AUTOSAR XML (schema 4-0-3)
package /ComponentTypes
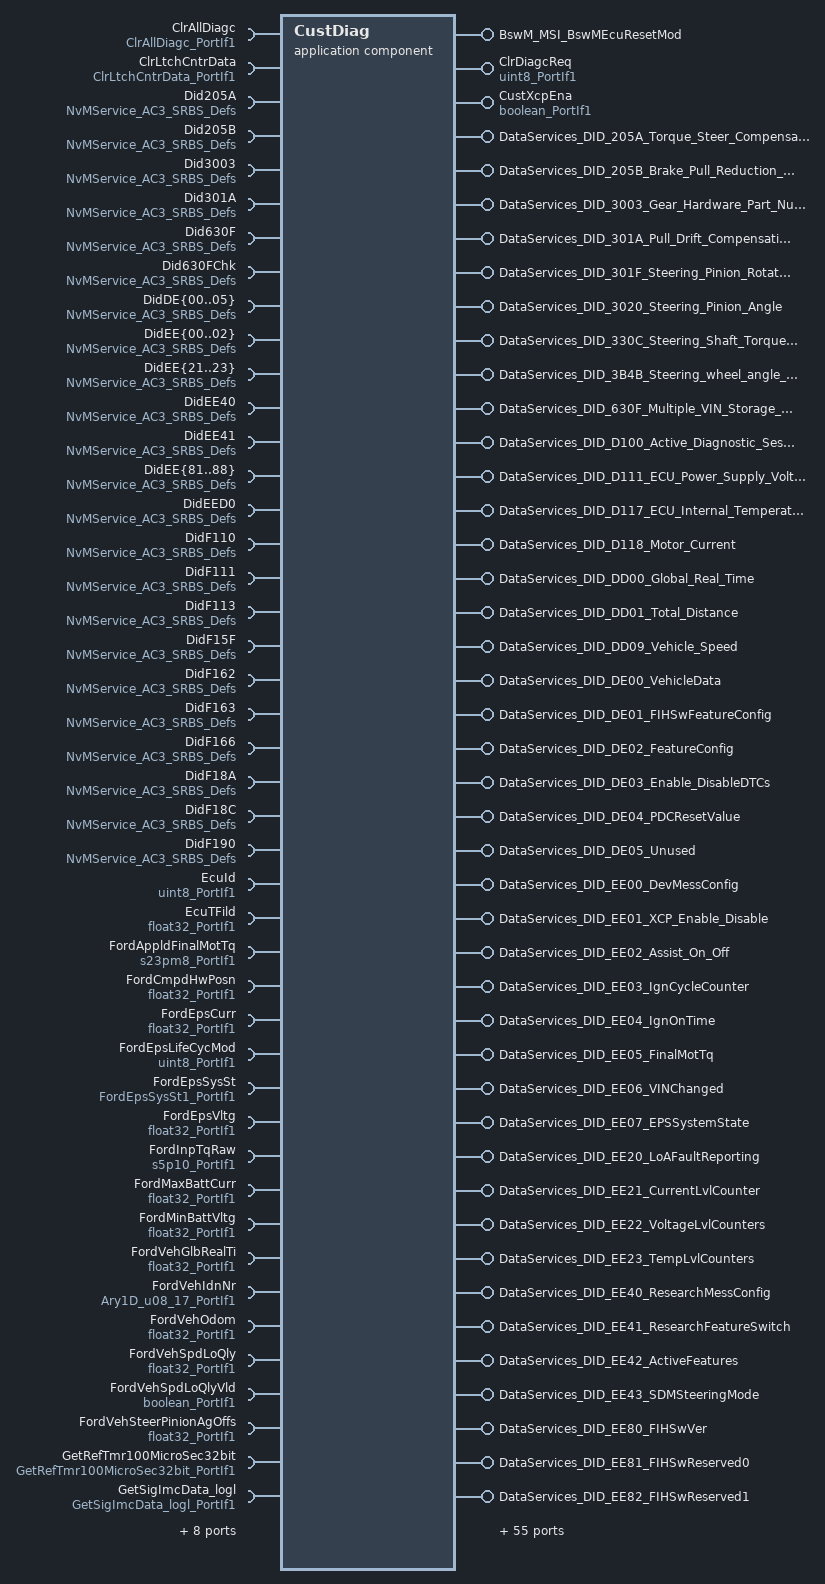
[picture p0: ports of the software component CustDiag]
  application sw component type CustDiag
    99 x provide port:
      BswM_MSI_BswMEcuResetMod: mode-switch-sender-com-spec{enhanced-mode-api=false, mode-group=BswM_MDGP_BswMEcuResetMod, queue-length=1}, provided-interface=BswM_MSI_BswMEcuResetMod
      ClrDiagcReq: nonqueued-sender-com-spec{data-element=Val, init-value=0}, provided-interface=uint8_PortIf1
      CustXcpEna: nonqueued-sender-com-spec{data-element=Logl, init-value=0}, provided-interface=boolean_PortIf1
      DataServices_DID_205A_Torque_Steer_Compensation_Activation_Counter: provided-interface=DataServices_DID_205A_Torque_Steer_Compensation_Activation_Counter
        provided-com-specs:
          operation=ConditionCheckRead, queue-length=1
          operation=ReadData, queue-length=1
          operation=WriteData, queue-length=1
      DataServices_DID_205B_Brake_Pull_Reduction_Activation_Counter: provided-interface=DataServices_DID_205B_Brake_Pull_Reduction_Activation_Counter
        provided-com-specs:
          operation=ConditionCheckRead, queue-length=1
          operation=ReadData, queue-length=1
          operation=WriteData, queue-length=1
      DataServices_DID_3003_Gear_Hardware_Part_Number: provided-interface=DataServices_DID_3003_Gear_Hardware_Part_Number
        provided-com-specs:
          operation=ConditionCheckRead, queue-length=1
          operation=ReadData, queue-length=1
          operation=WriteData, queue-length=1
      DataServices_DID_301A_Pull_Drift_Compensation_Value: provided-interface=DataServices_DID_301A_Pull_Drift_Compensation_Value
        provided-com-specs:
          operation=ConditionCheckRead, queue-length=1
          operation=ReadData, queue-length=1
          operation=WriteData, queue-length=1
      DataServices_DID_301F_Steering_Pinion_Rotation_Speed: provided-com-specs=[{operation=ConditionCheckRead, queue-length=1}, {operation=ReadData, queue-length=1}], provided-interface=DataServices_DID_301F_Steering_Pinion_Rotation_Speed
      DataServices_DID_3020_Steering_Pinion_Angle: provided-com-specs=[{operation=ConditionCheckRead, queue-length=1}, {operation=ReadData, queue-length=1}], provided-interface=DataServices_DID_3020_Steering_Pinion_Angle
      DataServices_DID_330C_Steering_Shaft_Torque_Sensor_2: provided-com-specs=[{operation=ConditionCheckRead, queue-length=1}, {operation=ReadData, queue-length=1}], provided-interface=DataServices_DID_330C_Steering_Shaft_Torque_Sensor_2
      DataServices_DID_3B4B_Steering_wheel_angle_alignment_offset: provided-com-specs=[{operation=ConditionCheckRead, queue-length=1}, {operation=ReadData, queue-length=1}], provided-interface=DataServices_DID_3B4B_Steering_wheel_angle_alignment_offset
      DataServices_DID_630F_Multiple_VIN_Storage_Original_VIN: provided-com-specs=[{operation=ConditionCheckRead, queue-length=1}, {operation=ReadData, queue-length=1}], provided-interface=DataServices_DID_630F_Multiple_VIN_Storage_Original_VIN
      DataServices_DID_D100_Active_Diagnostic_Session: provided-com-specs=[{operation=ConditionCheckRead, queue-length=1}, {operation=ReadData, queue-length=1}], provided-interface=DataServices_DID_D100_Active_Diagnostic_Session
      DataServices_DID_D111_ECU_Power_Supply_Voltage: provided-com-specs=[{operation=ConditionCheckRead, queue-length=1}, {operation=ReadData, queue-length=1}], provided-interface=DataServices_DID_D111_ECU_Power_Supply_Voltage
      DataServices_DID_D117_ECU_Internal_Temperature: provided-com-specs=[{operation=ConditionCheckRead, queue-length=1}, {operation=ReadData, queue-length=1}], provided-interface=DataServices_DID_D117_ECU_Internal_Temperature
      DataServices_DID_D118_Motor_Current: provided-com-specs=[{operation=ConditionCheckRead, queue-length=1}, {operation=ReadData, queue-length=1}], provided-interface=DataServices_DID_D118_Motor_Current
      DataServices_DID_DD00_Global_Real_Time: provided-com-specs=[{operation=ConditionCheckRead, queue-length=1}, {operation=ReadData, queue-length=1}], provided-interface=DataServices_DID_DD00_Global_Real_Time
      DataServices_DID_DD01_Total_Distance: provided-com-specs=[{operation=ConditionCheckRead, queue-length=1}, {operation=ReadData, queue-length=1}], provided-interface=DataServices_DID_DD01_Total_Distance
      DataServices_DID_DD09_Vehicle_Speed: provided-com-specs=[{operation=ConditionCheckRead, queue-length=1}, {operation=ReadData, queue-length=1}], provided-interface=DataServices_DID_DD09_Vehicle_Speed
      DataServices_DID_DE00_VehicleData: provided-interface=DataServices_DID_DE00_VehicleData
        provided-com-specs:
          operation=ConditionCheckRead, queue-length=1
          operation=ReadData, queue-length=1
          operation=WriteData, queue-length=1
      DataServices_DID_DE01_FIHSwFeatureConfig: provided-interface=DataServices_DID_DE01_FIHSwFeatureConfig
        provided-com-specs:
          operation=ConditionCheckRead, queue-length=1
          operation=ReadData, queue-length=1
          operation=WriteData, queue-length=1
      DataServices_DID_DE02_FeatureConfig: provided-interface=DataServices_DID_DE02_FeatureConfig
        provided-com-specs:
          operation=ConditionCheckRead, queue-length=1
          operation=ReadData, queue-length=1
          operation=WriteData, queue-length=1
      DataServices_DID_DE03_Enable_DisableDTCs: provided-interface=DataServices_DID_DE03_Enable_DisableDTCs
        provided-com-specs:
          operation=ConditionCheckRead, queue-length=1
          operation=ReadData, queue-length=1
          operation=WriteData, queue-length=1
      DataServices_DID_DE04_PDCResetValue: provided-interface=DataServices_DID_DE04_PDCResetValue
        provided-com-specs:
          operation=ConditionCheckRead, queue-length=1
          operation=ReadData, queue-length=1
          operation=WriteData, queue-length=1
      DataServices_DID_DE05_Unused: provided-interface=DataServices_DID_DE05_Unused
        provided-com-specs:
          operation=ConditionCheckRead, queue-length=1
          operation=ReadData, queue-length=1
          operation=WriteData, queue-length=1
      DataServices_DID_EE00_DevMessConfig: provided-interface=DataServices_DID_EE00_DevMessConfig
        provided-com-specs:
          operation=ConditionCheckRead, queue-length=1
          operation=ReadData, queue-length=1
          operation=WriteData, queue-length=1
      DataServices_DID_EE01_XCP_Enable_Disable: provided-interface=DataServices_DID_EE01_XCP_Enable_Disable
        provided-com-specs:
          operation=ConditionCheckRead, queue-length=1
          operation=ReadData, queue-length=1
          operation=WriteData, queue-length=1
      DataServices_DID_EE02_Assist_On_Off: provided-interface=DataServices_DID_EE02_Assist_On_Off
        provided-com-specs:
          operation=ConditionCheckRead, queue-length=1
          operation=ReadData, queue-length=1
          operation=WriteData, queue-length=1
      DataServices_DID_EE03_IgnCycleCounter: provided-com-specs=[{operation=ConditionCheckRead, queue-length=1}, {operation=ReadData, queue-length=1}], provided-interface=DataServices_DID_EE03_IgnCycleCounter
      DataServices_DID_EE04_IgnOnTime: provided-com-specs=[{operation=ConditionCheckRead, queue-length=1}, {operation=ReadData, queue-length=1}], provided-interface=DataServices_DID_EE04_IgnOnTime
      DataServices_DID_EE05_FinalMotTq: provided-com-specs=[{operation=ConditionCheckRead, queue-length=1}, {operation=ReadData, queue-length=1}], provided-interface=DataServices_DID_EE05_FinalMotTq
      DataServices_DID_EE06_VINChanged: provided-com-specs=[{operation=ConditionCheckRead, queue-length=1}, {operation=ReadData, queue-length=1}], provided-interface=DataServices_DID_EE06_VINChanged
      DataServices_DID_EE07_EPSSystemState: provided-com-specs=[{operation=ConditionCheckRead, queue-length=1}, {operation=ReadData, queue-length=1}], provided-interface=DataServices_DID_EE07_EPSSystemState
      DataServices_DID_EE20_LoAFaultReporting: provided-com-specs=[{operation=ConditionCheckRead, queue-length=1}, {operation=ReadData, queue-length=1}], provided-interface=DataServices_DID_EE20_LoAFaultReporting
      DataServices_DID_EE21_CurrentLvlCounter: provided-com-specs=[{operation=ConditionCheckRead, queue-length=1}, {operation=ReadData, queue-length=1}], provided-interface=DataServices_DID_EE21_CurrentLvlCounter
      DataServices_DID_EE22_VoltageLvlCounters: provided-com-specs=[{operation=ConditionCheckRead, queue-length=1}, {operation=ReadData, queue-length=1}], provided-interface=DataServices_DID_EE22_VoltageLvlCounters
      DataServices_DID_EE23_TempLvlCounters: provided-com-specs=[{operation=ConditionCheckRead, queue-length=1}, {operation=ReadData, queue-length=1}], provided-interface=DataServices_DID_EE23_TempLvlCounters
      DataServices_DID_EE40_ResearchMessConfig: provided-interface=DataServices_DID_EE40_ResearchMessConfig
        provided-com-specs:
          operation=ConditionCheckRead, queue-length=1
          operation=ReadData, queue-length=1
          operation=WriteData, queue-length=1
      DataServices_DID_EE41_ResearchFeatureSwitch: provided-interface=DataServices_DID_EE41_ResearchFeatureSwitch
        provided-com-specs:
          operation=ConditionCheckRead, queue-length=1
          operation=ReadData, queue-length=1
          operation=WriteData, queue-length=1
      DataServices_DID_EE42_ActiveFeatures: provided-com-specs=[{operation=ConditionCheckRead, queue-length=1}, {operation=ReadData, queue-length=1}], provided-interface=DataServices_DID_EE42_ActiveFeatures
      DataServices_DID_EE43_SDMSteeringMode: provided-com-specs=[{operation=ConditionCheckRead, queue-length=1}, {operation=ReadData, queue-length=1}], provided-interface=DataServices_DID_EE43_SDMSteeringMode
      DataServices_DID_EE80_FIHSwVer: provided-com-specs=[{operation=ConditionCheckRead, queue-length=1}, {operation=ReadData, queue-length=1}], provided-interface=DataServices_DID_EE80_FIHSwVer
      DataServices_DID_EE81_FIHSwReserved0: provided-interface=DataServices_DID_EE81_FIHSwReserved0
        provided-com-specs:
          operation=ConditionCheckRead, queue-length=1
          operation=ReadData, queue-length=1
          operation=WriteData, queue-length=1
      DataServices_DID_EE82_FIHSwReserved1: provided-interface=DataServices_DID_EE82_FIHSwReserved1
        provided-com-specs:
          operation=ConditionCheckRead, queue-length=1
          operation=ReadData, queue-length=1
          operation=WriteData, queue-length=1
      DataServices_DID_EE83_FIHSwReserved2: provided-interface=DataServices_DID_EE83_FIHSwReserved2
        provided-com-specs:
          operation=ConditionCheckRead, queue-length=1
          operation=ReadData, queue-length=1
          operation=WriteData, queue-length=1
      DataServices_DID_EE84_FIHSwReserved3: provided-interface=DataServices_DID_EE84_FIHSwReserved3
        provided-com-specs:
          operation=ConditionCheckRead, queue-length=1
          operation=ReadData, queue-length=1
          operation=WriteData, queue-length=1
      DataServices_DID_EE85_FIHSwReserved4: provided-interface=DataServices_DID_EE85_FIHSwReserved4
        provided-com-specs:
          operation=ConditionCheckRead, queue-length=1
          operation=ReadData, queue-length=1
          operation=WriteData, queue-length=1
      DataServices_DID_EE86_FIHSwReserved5: provided-interface=DataServices_DID_EE86_FIHSwReserved5
        provided-com-specs:
          operation=ConditionCheckRead, queue-length=1
          operation=ReadData, queue-length=1
          operation=WriteData, queue-length=1
      DataServices_DID_EE87_FIHSwReserved6: provided-interface=DataServices_DID_EE87_FIHSwReserved6
        provided-com-specs:
          operation=ConditionCheckRead, queue-length=1
          operation=ReadData, queue-length=1
          operation=WriteData, queue-length=1
      DataServices_DID_EE88_FIHSwReserved7: provided-interface=DataServices_DID_EE88_FIHSwReserved7
        provided-com-specs:
          operation=ConditionCheckRead, queue-length=1
          operation=ReadData, queue-length=1
          operation=WriteData, queue-length=1
      DataServices_DID_EED0_SupplierFactoryMode: provided-interface=DataServices_DID_EED0_SupplierFactoryMode
        provided-com-specs:
          operation=ConditionCheckRead, queue-length=1
          operation=ReadData, queue-length=1
          operation=WriteData, queue-length=1
      DataServices_DID_EED1_SupplierInternalFaultCode: provided-com-specs=[{operation=ConditionCheckRead, queue-length=1}, {operation=ReadData, queue-length=1}], provided-interface=DataServices_DID_EED1_SupplierInternalFaultCode
      DataServices_DID_EED2_SupplierInternalErrorMemory: provided-com-specs=[{operation=ConditionCheckRead, queue-length=1}, {operation=ReadData, queue-length=1}], provided-interface=DataServices_DID_EED2_SupplierInternalErrorMemory
      DataServices_DID_F10A_ECU_Cal_Config_Part_Number: provided-com-specs=[{operation=ConditionCheckRead, queue-length=1}, {operation=ReadData, queue-length=1}], provided-interface=DataServices_DID_F10A_ECU_Cal_Config_Part_Number
      DataServices_DID_F110_Subsystem_Specific_Diagnostic_Specification_Part_Number: provided-interface=DataServices_DID_F110_Subsystem_Specific_Diagnostic_Specification_Part_Number
        provided-com-specs:
          operation=ConditionCheckRead, queue-length=1
          operation=ReadData, queue-length=1
          operation=WriteData, queue-length=1
      DataServices_DID_F111_ECU_Core_Assembly_Number: provided-interface=DataServices_DID_F111_ECU_Core_Assembly_Number
        provided-com-specs:
          operation=ConditionCheckRead, queue-length=1
          operation=ReadData, queue-length=1
          operation=WriteData, queue-length=1
      DataServices_DID_F113_ECU_Delivery_Assembly_Number: provided-interface=DataServices_DID_F113_ECU_Delivery_Assembly_Number
        provided-com-specs:
          operation=ConditionCheckRead, queue-length=1
          operation=ReadData, queue-length=1
          operation=WriteData, queue-length=1
      DataServices_DID_F124_ECU_Calibration_Data_1_Number: provided-com-specs=[{operation=ConditionCheckRead, queue-length=1}, {operation=ReadData, queue-length=1}], provided-interface=DataServices_DID_F124_ECU_Calibration_Data_1_Number
      DataServices_DID_F15F_NOS_Generation_Tool_Version_Number: provided-com-specs=[{operation=ConditionCheckRead, queue-length=1}, {operation=ReadData, queue-length=1}], provided-interface=DataServices_DID_F15F_NOS_Generation_Tool_Version_Number
      DataServices_DID_F162_Software_Download_Specification_Version: provided-interface=DataServices_DID_F162_Software_Download_Specification_Version
        provided-com-specs:
          operation=ConditionCheckRead, queue-length=1
          operation=ReadData, queue-length=1
          operation=WriteData, queue-length=1
      DataServices_DID_F163_Diagnostic_Specification_Version: provided-interface=DataServices_DID_F163_Diagnostic_Specification_Version
        provided-com-specs:
          operation=ConditionCheckRead, queue-length=1
          operation=ReadData, queue-length=1
          operation=WriteData, queue-length=1
      DataServices_DID_F166_NOS_Message_Database_1_Version_Number: provided-interface=DataServices_DID_F166_NOS_Message_Database_1_Version_Number
        provided-com-specs:
          operation=ConditionCheckRead, queue-length=1
          operation=ReadData, queue-length=1
          operation=WriteData, queue-length=1
      DataServices_DID_F17C_NOS_Bootloader_Generation_Tool_Version_Number: provided-com-specs=[{operation=ConditionCheckRead, queue-length=1}, {operation=ReadData, queue-length=1}], provided-interface=DataServices_DID_F17C_NOS_Bootloader_Generation_Tool_Version_Number
      DataServices_DID_F180_Boot_Software_Identification: provided-com-specs=[{operation=ConditionCheckRead, queue-length=1}, {operation=ReadData, queue-length=1}], provided-interface=DataServices_DID_F180_Boot_Software_Identification
      DataServices_DID_F188_Vehicle_Manufacturer_ECU_Software_Number: provided-com-specs=[{operation=ConditionCheckRead, queue-length=1}, {operation=ReadData, queue-length=1}], provided-interface=DataServices_DID_F188_Vehicle_Manufacturer_ECU_Software_Number
      DataServices_DID_F18A_System_Supplier_Identifier: provided-interface=DataServices_DID_F18A_System_Supplier_Identifier
        provided-com-specs:
          operation=ConditionCheckRead, queue-length=1
          operation=ReadData, queue-length=1
          operation=WriteData, queue-length=1
      DataServices_DID_F18C_ECU_Serial_Number: provided-interface=DataServices_DID_F18C_ECU_Serial_Number
        provided-com-specs:
          operation=ConditionCheckRead, queue-length=1
          operation=ReadData, queue-length=1
          operation=WriteData, queue-length=1
      DataServices_DID_F190_Vehicle_Identification_Number: provided-com-specs=[{operation=ConditionCheckRead, queue-length=1}, {operation=ReadData, queue-length=1}], provided-interface=DataServices_DID_F190_Vehicle_Identification_Number
      FordAbsPrsnt: nonqueued-sender-com-spec{data-element=Logl, init-value=1}, provided-interface=boolean_PortIf1
      FordActvNiblCtrlEnad: nonqueued-sender-com-spec{data-element=Logl, init-value=0}, provided-interface=boolean_PortIf1
      FordActvParkAssiEnad: nonqueued-sender-com-spec{data-element=Logl, init-value=0}, provided-interface=boolean_PortIf1
      FordActvRtnEnad: nonqueued-sender-com-spec{data-element=Logl, init-value=1}, provided-interface=boolean_PortIf1
      FordAfsEquid: nonqueued-sender-com-spec{data-element=Logl, init-value=0}, provided-interface=boolean_PortIf1
      FordBrkPlsRejctnEnad: nonqueued-sender-com-spec{data-element=Logl, init-value=0}, provided-interface=boolean_PortIf1
      FordDrvrSteerRcmdnEnad: nonqueued-sender-com-spec{data-element=Logl, init-value=0}, provided-interface=boolean_PortIf1
      FordEngTqClass: nonqueued-sender-com-spec{data-element=Val, init-value=2}, provided-interface=uint8_PortIf1
      FordEscPrsnt: nonqueued-sender-com-spec{data-element=Logl, init-value=1}, provided-interface=boolean_PortIf1
      FordEvasSteerAssiEnad: nonqueued-sender-com-spec{data-element=Logl, init-value=0}, provided-interface=boolean_PortIf1
      FordLaneCentrAssiEnad: nonqueued-sender-com-spec{data-element=Logl, init-value=0}, provided-interface=boolean_PortIf1
      FordLaneDprtrWarnEnad: nonqueued-sender-com-spec{data-element=Logl, init-value=0}, provided-interface=boolean_PortIf1
      FordLaneKeepAssiEnad: nonqueued-sender-com-spec{data-element=Logl, init-value=0}, provided-interface=boolean_PortIf1
      FordPullDriftCmpEnad: nonqueued-sender-com-spec{data-element=Logl, init-value=0}, provided-interface=boolean_PortIf1
      FordResrchFctEnad: nonqueued-sender-com-spec{data-element=Logl, init-value=0}, provided-interface=boolean_PortIf1
      FordSelDrvModEnad: nonqueued-sender-com-spec{data-element=Logl, init-value=0}, provided-interface=boolean_PortIf1
      FordSoftEndStopEnad: nonqueued-sender-com-spec{data-element=Logl, init-value=0}, provided-interface=boolean_PortIf1
      FordSrvPullDriftCmpRstVal: nonqueued-sender-com-spec{data-element=Val, init-value=0}, provided-interface=sint16_PortIf1
      FordStrtStopSt: nonqueued-sender-com-spec{data-element=Val, init-value=0}, provided-interface=uint8_PortIf1
      FordTqSteerCmpEnad: nonqueued-sender-com-spec{data-element=Logl, init-value=0}, provided-interface=boolean_PortIf1
      FordTrfcJamAssiEnad: nonqueued-sender-com-spec{data-element=Logl, init-value=0}, provided-interface=boolean_PortIf1
      FordTrlrBackupAssi5WhlEnad: nonqueued-sender-com-spec{data-element=Logl, init-value=0}, provided-interface=boolean_PortIf1
      FordTrlrBackupAssiEnad: nonqueued-sender-com-spec{data-element=Logl, init-value=0}, provided-interface=boolean_PortIf1
      FordTrlrBackupAssiTrigEnad: nonqueued-sender-com-spec{data-element=Logl, init-value=0}, provided-interface=boolean_PortIf1
      RoutineServices_RTN_0202_On_Demand_Self_Test: provided-interface=RoutineServices_RTN_0202_On_Demand_Self_Test
        provided-com-specs:
          operation=RequestResults, queue-length=1
          operation=Start, queue-length=1
          operation=Stop, queue-length=1
      RoutineServices_RTN_200E_Calibrate_Steering_Angle_Centre_Position: server-com-spec{operation=Start, queue-length=1}, provided-interface=RoutineServices_RTN_200E_Calibrate_Steering_Angle_Centre_Position
      RoutineServices_RTN_200F_Clear_Steering_Angle_Centre_Position_Calibration: server-com-spec{operation=Start, queue-length=1}, provided-interface=RoutineServices_RTN_200F_Clear_Steering_Angle_Centre_Position_Calibration
      RoutineServices_RTN_DC00_Reset_Assist_Fault_Counters: server-com-spec{operation=Start, queue-length=1}, provided-interface=RoutineServices_RTN_DC00_Reset_Assist_Fault_Counters
      RstReq: nonqueued-sender-com-spec{data-element=Val, init-value=0}, provided-interface=uint8_PortIf1
      RtnDC00Req: nonqueued-sender-com-spec{data-element=Val, init-value=0}, provided-interface=uint8_PortIf1
      ServiceRequestNotification: provided-com-specs=[{operation=Confirmation, queue-length=1}, {operation=Indication, queue-length=1}], provided-interface=ServiceRequestNotification
    68 x require port:
      ClrAllDiagc: client-com-spec=Oper, required-interface=ClrAllDiagc_PortIf1
      ClrLtchCntrData: client-com-spec=Oper, required-interface=ClrLtchCntrData_PortIf1
      Did205A: required-com-specs=[EraseBlock, GetErrorStatus, InvalidateNvBlock, ReadBlock, RestoreBlockDefaults, SetRamBlockStatus, WriteBlock], required-interface=NvMService_AC3_SRBS_Defs
      Did205B: required-com-specs=[EraseBlock, GetErrorStatus, InvalidateNvBlock, ReadBlock, RestoreBlockDefaults, SetRamBlockStatus, WriteBlock], required-interface=NvMService_AC3_SRBS_Defs
      Did3003: required-com-specs=[EraseBlock, GetErrorStatus, InvalidateNvBlock, ReadBlock, RestoreBlockDefaults, SetRamBlockStatus, WriteBlock], required-interface=NvMService_AC3_SRBS_Defs
      Did301A: required-com-specs=[EraseBlock, GetErrorStatus, InvalidateNvBlock, ReadBlock, RestoreBlockDefaults, SetRamBlockStatus, WriteBlock], required-interface=NvMService_AC3_SRBS_Defs
      Did630F: required-com-specs=[EraseBlock, GetErrorStatus, InvalidateNvBlock, ReadBlock, RestoreBlockDefaults, SetRamBlockStatus, WriteBlock], required-interface=NvMService_AC3_SRBS_Defs
      Did630FChk: required-com-specs=[EraseBlock, GetErrorStatus, InvalidateNvBlock, ReadBlock, RestoreBlockDefaults, SetRamBlockStatus, WriteBlock], required-interface=NvMService_AC3_SRBS_Defs
      DidDE{00..05}: required-com-specs=[EraseBlock, GetErrorStatus, InvalidateNvBlock, ReadBlock, RestoreBlockDefaults, SetRamBlockStatus, WriteBlock], required-interface=NvMService_AC3_SRBS_Defs
      DidEE{00..02}: required-com-specs=[EraseBlock, GetErrorStatus, InvalidateNvBlock, ReadBlock, RestoreBlockDefaults, SetRamBlockStatus, WriteBlock], required-interface=NvMService_AC3_SRBS_Defs
      DidEE{21..23}: required-com-specs=[EraseBlock, GetErrorStatus, InvalidateNvBlock, ReadBlock, RestoreBlockDefaults, SetRamBlockStatus, WriteBlock], required-interface=NvMService_AC3_SRBS_Defs
      DidEE40: required-com-specs=[EraseBlock, GetErrorStatus, InvalidateNvBlock, ReadBlock, RestoreBlockDefaults, SetRamBlockStatus, WriteBlock], required-interface=NvMService_AC3_SRBS_Defs
      DidEE41: required-com-specs=[EraseBlock, GetErrorStatus, InvalidateNvBlock, ReadBlock, RestoreBlockDefaults, SetRamBlockStatus, WriteBlock], required-interface=NvMService_AC3_SRBS_Defs
      DidEE{81..88}: required-com-specs=[EraseBlock, GetErrorStatus, InvalidateNvBlock, ReadBlock, RestoreBlockDefaults, SetRamBlockStatus, WriteBlock], required-interface=NvMService_AC3_SRBS_Defs
      DidEED0: required-com-specs=[EraseBlock, GetErrorStatus, InvalidateNvBlock, ReadBlock, RestoreBlockDefaults, SetRamBlockStatus, WriteBlock], required-interface=NvMService_AC3_SRBS_Defs
      DidF110: required-com-specs=[EraseBlock, GetErrorStatus, InvalidateNvBlock, ReadBlock, RestoreBlockDefaults, SetRamBlockStatus, WriteBlock], required-interface=NvMService_AC3_SRBS_Defs
      DidF111: required-com-specs=[EraseBlock, GetErrorStatus, InvalidateNvBlock, ReadBlock, RestoreBlockDefaults, SetRamBlockStatus, WriteBlock], required-interface=NvMService_AC3_SRBS_Defs
      DidF113: required-com-specs=[EraseBlock, GetErrorStatus, InvalidateNvBlock, ReadBlock, RestoreBlockDefaults, SetRamBlockStatus, WriteBlock], required-interface=NvMService_AC3_SRBS_Defs
      DidF15F: required-com-specs=[EraseBlock, GetErrorStatus, InvalidateNvBlock, ReadBlock, RestoreBlockDefaults, SetRamBlockStatus, WriteBlock], required-interface=NvMService_AC3_SRBS_Defs
      DidF162: required-com-specs=[EraseBlock, GetErrorStatus, InvalidateNvBlock, ReadBlock, RestoreBlockDefaults, SetRamBlockStatus, WriteBlock], required-interface=NvMService_AC3_SRBS_Defs
      DidF163: required-com-specs=[EraseBlock, GetErrorStatus, InvalidateNvBlock, ReadBlock, RestoreBlockDefaults, SetRamBlockStatus, WriteBlock], required-interface=NvMService_AC3_SRBS_Defs
      DidF166: required-com-specs=[EraseBlock, GetErrorStatus, InvalidateNvBlock, ReadBlock, RestoreBlockDefaults, SetRamBlockStatus, WriteBlock], required-interface=NvMService_AC3_SRBS_Defs
      DidF18A: required-com-specs=[EraseBlock, GetErrorStatus, InvalidateNvBlock, ReadBlock, RestoreBlockDefaults, SetRamBlockStatus, WriteBlock], required-interface=NvMService_AC3_SRBS_Defs
      DidF18C: required-com-specs=[EraseBlock, GetErrorStatus, InvalidateNvBlock, ReadBlock, RestoreBlockDefaults, SetRamBlockStatus, WriteBlock], required-interface=NvMService_AC3_SRBS_Defs
      DidF190: required-com-specs=[EraseBlock, GetErrorStatus, InvalidateNvBlock, ReadBlock, RestoreBlockDefaults, SetRamBlockStatus, WriteBlock], required-interface=NvMService_AC3_SRBS_Defs
      EcuId: nonqueued-receiver-com-spec{data-element=Val, filter=data-filter-type=ALWAYS, init-value=0}, required-interface=uint8_PortIf1
      EcuTFild: nonqueued-receiver-com-spec{data-element=Val, filter=data-filter-type=ALWAYS, init-value=25}, required-interface=float32_PortIf1
      FordAppldFinalMotTq: nonqueued-receiver-com-spec{data-element=Val, filter=data-filter-type=ALWAYS}, required-interface=s23pm8_PortIf1
      FordCmpdHwPosn: nonqueued-receiver-com-spec{data-element=Val, filter=data-filter-type=ALWAYS, init-value=0}, required-interface=float32_PortIf1
      FordEpsCurr: nonqueued-receiver-com-spec{data-element=Val, filter=data-filter-type=ALWAYS, init-value=140.75}, required-interface=float32_PortIf1
      FordEpsLifeCycMod: nonqueued-receiver-com-spec{data-element=Val, filter=data-filter-type=ALWAYS, init-value=0}, required-interface=uint8_PortIf1
      FordEpsSysSt: nonqueued-receiver-com-spec{data-element=Val, filter=data-filter-type=ALWAYS, init-value=0}, required-interface=FordEpsSysSt1_PortIf1
      FordEpsVltg: nonqueued-receiver-com-spec{data-element=Val, filter=data-filter-type=ALWAYS, init-value=18.75}, required-interface=float32_PortIf1
      FordInpTqRaw: nonqueued-receiver-com-spec{data-element=Val, filter=data-filter-type=ALWAYS}, required-interface=s5p10_PortIf1  # Processed value of Input Torque Raw
      FordMaxBattCurr: nonqueued-receiver-com-spec{data-element=Val, filter=data-filter-type=ALWAYS, init-value=0}, required-interface=float32_PortIf1
      FordMinBattVltg: nonqueued-receiver-com-spec{data-element=Val, filter=data-filter-type=ALWAYS, init-value=0}, required-interface=float32_PortIf1
      FordVehGlbRealTi: nonqueued-receiver-com-spec{data-element=Val, filter=data-filter-type=ALWAYS, init-value=0.1}, required-interface=float32_PortIf1
      FordVehIdnNr: nonqueued-receiver-com-spec{data-element=Ary1D, filter=data-filter-type=ALWAYS, init-value=17 x 0}, required-interface=Ary1D_u08_17_PortIf1
      FordVehOdom: nonqueued-receiver-com-spec{data-element=Val, filter=data-filter-type=ALWAYS, init-value=0}, required-interface=float32_PortIf1
      FordVehSpdLoQly: nonqueued-receiver-com-spec{data-element=Val, filter=data-filter-type=ALWAYS, init-value=0}, required-interface=float32_PortIf1
      FordVehSpdLoQlyVld: nonqueued-receiver-com-spec{data-element=Logl, filter=data-filter-type=ALWAYS, init-value=0}, required-interface=boolean_PortIf1
      FordVehSteerPinionAgOffs: nonqueued-receiver-com-spec{data-element=Val, filter=data-filter-type=ALWAYS, init-value=0}, required-interface=float32_PortIf1
      GetRefTmr100MicroSec32bit: client-com-spec=Oper, required-interface=GetRefTmr100MicroSec32bit_PortIf1
      GetSigImcData_logl: client-com-spec=Oper, required-interface=GetSigImcData_logl_PortIf1
      GetSigImcData_u08: client-com-spec=Oper, required-interface=GetSigImcData_u08_PortIf1
      HwVelToSerlCom: nonqueued-receiver-com-spec{data-element=Val, filter=data-filter-type=ALWAYS, init-value=0}, required-interface=float32_PortIf1
      IgnCntr: nonqueued-receiver-com-spec{data-element=Val, filter=data-filter-type=ALWAYS, init-value=0}, required-interface=uint32_PortIf1
      MotCurrQax: nonqueued-receiver-com-spec{data-element=Val, filter=data-filter-type=ALWAYS, init-value=0}, required-interface=float32_PortIf1
      NxtrCalIdsCal0DevlpDesc: parameter-require-com-spec=Ary1D, required-interface=Ary1D_u8_48_CalPortIf1
      NxtrCalIdsCal1DevlpDesc: parameter-require-com-spec=Ary1D, required-interface=Ary1D_u8_48_CalPortIf1
      SetNtcSts: client-com-spec=Oper, required-interface=SetNtcSts_PortIf1
      VehSpd: nonqueued-receiver-com-spec{data-element=Val, filter=data-filter-type=ALWAYS, init-value=0}, required-interface=float32_PortIf1
    behavior CustDiag_InternalBehavior
      ar-typed-per-instance-memorys:
        51 x data, all with sw-calibration-access=READ-ONLY:
          ClrDiagcReq: type=uint8
          Did205A: type=Ary1D_u8_2
          Did205B: type=Ary1D_u8_2
          Did3003: type=Ary1D_u8_24
          Did301A: type=Ary1D_u8_2
          Did630F: type=Ary1D_u8_24
          Did630FChk: type=boolean
          DidDE{00..02}: type=Ary1D_u8_24
          DidDE03: type=Ary1D_u8_64
          DidDE04: type=Ary1D_u8_2
          DidDE05: type=Ary1D_u8_24
          DidEE00: type=Ary1D_u8_3
          DidEE01: type=uint8
          DidEE02: type=uint8
          DidEE21: type=Ary1D_u8_20
          DidEE22: type=Ary1D_u8_40
          DidEE23: type=Ary1D_u8_40
          DidEE40: type=Ary1D_u8_3
          DidEE41: type=uint8
          DidEE{81..88}: type=Ary1D_u8_4
          DidEED0: type=uint8
          DidF110: type=Ary1D_u8_24
          DidF111: type=Ary1D_u8_24
          DidF113: type=Ary1D_u8_24
          DidF15F: type=Ary1D_u8_10
          DidF162: type=uint8
          DidF163: type=uint8
          DidF166: type=Ary1D_u8_4
          DidF18A: type=Ary1D_u8_24
          DidF18C: type=Ary1D_u8_16
          DidF190: type=Ary1D_u8_24
          EcuId: type=uint8
          EcuResetMode: type=BswM_BswMEcuResetMod
          EolByteNTCPara: type=uint8
          MaxCurr: type=float32
          MaxTemp: type=float32
          MinVltg: type=float32
          ReqDelayCnt: type=uint8
          RstReq: type=uint8
          RstStrt: type=uint8
          Rtn0202Strt: type=boolean
          RtnDC00Req: type=uint8
      4 x timing event:
        CustDiag_InitEvent: start-on-event=CustDiagInit1, period=0
        TMT_CustDiagPer1: start-on-event=CustDiagPer1, period=0.002
        TMT_CustDiagPer2: start-on-event=CustDiagPer2, period=0.01
        TMT_CustDiagPer3: start-on-event=CustDiagPer3, period=0.1
      170 x operation invoked event:
        OIT_Customer_DID_ConditionCheckRead_DataServices_DID_205A_Torque_Steer_Compensation_Activation_Counter_ConditionCheckRead: start-on-event=Customer_DID_ConditionCheckRead, operation=DataServices_DID_205A_Torque_Steer_Compensation_Activation_Counter.ConditionCheckRead
        OIT_Customer_DID_ConditionCheckRead_DataServices_DID_205B_Brake_Pull_Reduction_Activation_Counter_ConditionCheckRead: start-on-event=Customer_DID_ConditionCheckRead, operation=DataServices_DID_205B_Brake_Pull_Reduction_Activation_Counter.ConditionCheckRead
        OIT_Customer_DID_ConditionCheckRead_DataServices_DID_3003_Gear_Hardware_Part_Number_ConditionCheckRead: start-on-event=Customer_DID_ConditionCheckRead, operation=DataServices_DID_3003_Gear_Hardware_Part_Number.ConditionCheckRead
        OIT_Customer_DID_ConditionCheckRead_DataServices_DID_301A_Pull_Drift_Compensation_Value_ConditionCheckRead: start-on-event=Customer_DID_ConditionCheckRead, operation=DataServices_DID_301A_Pull_Drift_Compensation_Value.ConditionCheckRead
        OIT_Customer_DID_ConditionCheckRead_DataServices_DID_301F_Steering_Pinion_Rotation_Speed_ConditionCheckRead: start-on-event=Customer_DID_ConditionCheckRead, operation=DataServices_DID_301F_Steering_Pinion_Rotation_Speed.ConditionCheckRead
        OIT_Customer_DID_ConditionCheckRead_DataServices_DID_3020_Steering_Pinion_Angle_ConditionCheckRead: start-on-event=Customer_DID_ConditionCheckRead, operation=DataServices_DID_3020_Steering_Pinion_Angle.ConditionCheckRead
        OIT_Customer_DID_ConditionCheckRead_DataServices_DID_330C_Steering_Shaft_Torque_Sensor_2_ConditionCheckRead: start-on-event=Customer_DID_ConditionCheckRead, operation=DataServices_DID_330C_Steering_Shaft_Torque_Sensor_2.ConditionCheckRead
        OIT_Customer_DID_ConditionCheckRead_DataServices_DID_3B4B_Steering_wheel_angle_alignment_offset_ConditionCheckRead: start-on-event=Customer_DID_ConditionCheckRead, operation=DataServices_DID_3B4B_Steering_wheel_angle_alignment_offset.ConditionCheckRead
        OIT_Customer_DID_ConditionCheckRead_DataServices_DID_630F_Multiple_VIN_Storage_Original_VIN_ConditionCheckRead: start-on-event=Customer_DID_ConditionCheckRead, operation=DataServices_DID_630F_Multiple_VIN_Storage_Original_VIN.ConditionCheckRead
        OIT_Customer_DID_ConditionCheckRead_DataServices_DID_D100_Active_Diagnostic_Session_ConditionCheckRead: start-on-event=Customer_DID_ConditionCheckRead, operation=DataServices_DID_D100_Active_Diagnostic_Session.ConditionCheckRead
        OIT_Customer_DID_ConditionCheckRead_DataServices_DID_D111_ECU_Power_Supply_Voltage_ConditionCheckRead: start-on-event=Customer_DID_ConditionCheckRead, operation=DataServices_DID_D111_ECU_Power_Supply_Voltage.ConditionCheckRead
        OIT_Customer_DID_ConditionCheckRead_DataServices_DID_D117_ECU_Internal_Temperature_ConditionCheckRead: start-on-event=Customer_DID_ConditionCheckRead, operation=DataServices_DID_D117_ECU_Internal_Temperature.ConditionCheckRead
        OIT_Customer_DID_ConditionCheckRead_DataServices_DID_D118_Motor_Current_ConditionCheckRead: start-on-event=Customer_DID_ConditionCheckRead, operation=DataServices_DID_D118_Motor_Current.ConditionCheckRead
        OIT_Customer_DID_ConditionCheckRead_DataServices_DID_DD00_Global_Real_Time_ConditionCheckRead: start-on-event=Customer_DID_ConditionCheckRead, operation=DataServices_DID_DD00_Global_Real_Time.ConditionCheckRead
        OIT_Customer_DID_ConditionCheckRead_DataServices_DID_DD01_Total_Distance_ConditionCheckRead: start-on-event=Customer_DID_ConditionCheckRead, operation=DataServices_DID_DD01_Total_Distance.ConditionCheckRead
        OIT_Customer_DID_ConditionCheckRead_DataServices_DID_DD09_Vehicle_Speed_ConditionCheckRead: start-on-event=Customer_DID_ConditionCheckRead, operation=DataServices_DID_DD09_Vehicle_Speed.ConditionCheckRead
        OIT_Customer_DID_ConditionCheckRead_DataServices_DID_DE00_VehicleData_ConditionCheckRead: start-on-event=Customer_DID_ConditionCheckRead, operation=DataServices_DID_DE00_VehicleData.ConditionCheckRead
        OIT_Customer_DID_ConditionCheckRead_DataServices_DID_DE01_FIHSwFeatureConfig_ConditionCheckRead: start-on-event=Customer_DID_ConditionCheckRead, operation=DataServices_DID_DE01_FIHSwFeatureConfig.ConditionCheckRead
        OIT_Customer_DID_ConditionCheckRead_DataServices_DID_DE02_FeatureConfig_ConditionCheckRead: start-on-event=Customer_DID_ConditionCheckRead, operation=DataServices_DID_DE02_FeatureConfig.ConditionCheckRead
        OIT_Customer_DID_ConditionCheckRead_DataServices_DID_DE03_Enable_DisableDTCs_ConditionCheckRead: start-on-event=Customer_DID_ConditionCheckRead, operation=DataServices_DID_DE03_Enable_DisableDTCs.ConditionCheckRead
        OIT_Customer_DID_ConditionCheckRead_DataServices_DID_DE04_PDCResetValue_ConditionCheckRead: start-on-event=Customer_DID_ConditionCheckRead, operation=DataServices_DID_DE04_PDCResetValue.ConditionCheckRead
        OIT_Customer_DID_ConditionCheckRead_DataServices_DID_DE05_Unused_ConditionCheckRead: start-on-event=Customer_DID_ConditionCheckRead, operation=DataServices_DID_DE05_Unused.ConditionCheckRead
        OIT_Customer_DID_ConditionCheckRead_DataServices_DID_EE00_DevMessConfig_ConditionCheckRead: start-on-event=Customer_DID_ConditionCheckRead, operation=DataServices_DID_EE00_DevMessConfig.ConditionCheckRead
        OIT_Customer_DID_ConditionCheckRead_DataServices_DID_EE01_XCP_Enable_Disable_ConditionCheckRead: start-on-event=Customer_DID_ConditionCheckRead, operation=DataServices_DID_EE01_XCP_Enable_Disable.ConditionCheckRead
        OIT_Customer_DID_ConditionCheckRead_DataServices_DID_EE02_Assist_On_Off_ConditionCheckRead: start-on-event=Customer_DID_ConditionCheckRead, operation=DataServices_DID_EE02_Assist_On_Off.ConditionCheckRead
        OIT_Customer_DID_ConditionCheckRead_DataServices_DID_EE03_IgnCycleCounter_ConditionCheckRead: start-on-event=Customer_DID_ConditionCheckRead, operation=DataServices_DID_EE03_IgnCycleCounter.ConditionCheckRead
        OIT_Customer_DID_ConditionCheckRead_DataServices_DID_EE04_IgnOnTime_ConditionCheckRead: start-on-event=Customer_DID_ConditionCheckRead, operation=DataServices_DID_EE04_IgnOnTime.ConditionCheckRead
        OIT_Customer_DID_ConditionCheckRead_DataServices_DID_EE05_FinalMotTq_ConditionCheckRead: start-on-event=Customer_DID_ConditionCheckRead, operation=DataServices_DID_EE05_FinalMotTq.ConditionCheckRead
        OIT_Customer_DID_ConditionCheckRead_DataServices_DID_EE06_VINChanged_ConditionCheckRead: start-on-event=Customer_DID_ConditionCheckRead, operation=DataServices_DID_EE06_VINChanged.ConditionCheckRead
        OIT_Customer_DID_ConditionCheckRead_DataServices_DID_EE07_EPSSystemState_ConditionCheckRead: start-on-event=Customer_DID_ConditionCheckRead, operation=DataServices_DID_EE07_EPSSystemState.ConditionCheckRead
        OIT_Customer_DID_ConditionCheckRead_DataServices_DID_EE20_LoAFaultReporting_ConditionCheckRead: start-on-event=Customer_DID_ConditionCheckRead, operation=DataServices_DID_EE20_LoAFaultReporting.ConditionCheckRead
        OIT_Customer_DID_ConditionCheckRead_DataServices_DID_EE21_CurrentLvlCounter_ConditionCheckRead: start-on-event=Customer_DID_ConditionCheckRead, operation=DataServices_DID_EE21_CurrentLvlCounter.ConditionCheckRead
        OIT_Customer_DID_ConditionCheckRead_DataServices_DID_EE22_VoltageLvlCounters_ConditionCheckRead: start-on-event=Customer_DID_ConditionCheckRead, operation=DataServices_DID_EE22_VoltageLvlCounters.ConditionCheckRead
        OIT_Customer_DID_ConditionCheckRead_DataServices_DID_EE23_TempLvlCounters_ConditionCheckRead: start-on-event=Customer_DID_ConditionCheckRead, operation=DataServices_DID_EE23_TempLvlCounters.ConditionCheckRead
        OIT_Customer_DID_ConditionCheckRead_DataServices_DID_EE40_ResearchMessConfig_ConditionCheckRead: start-on-event=Customer_DID_ConditionCheckRead, operation=DataServices_DID_EE40_ResearchMessConfig.ConditionCheckRead
        OIT_Customer_DID_ConditionCheckRead_DataServices_DID_EE41_ResearchFeatureSwitch_ConditionCheckRead: start-on-event=Customer_DID_ConditionCheckRead, operation=DataServices_DID_EE41_ResearchFeatureSwitch.ConditionCheckRead
        OIT_Customer_DID_ConditionCheckRead_DataServices_DID_EE42_ActiveFeatures_ConditionCheckRead: start-on-event=Customer_DID_ConditionCheckRead, operation=DataServices_DID_EE42_ActiveFeatures.ConditionCheckRead
        OIT_Customer_DID_ConditionCheckRead_DataServices_DID_EE43_SDMSteeringMode_ConditionCheckRead: start-on-event=Customer_DID_ConditionCheckRead, operation=DataServices_DID_EE43_SDMSteeringMode.ConditionCheckRead
        OIT_Customer_DID_ConditionCheckRead_DataServices_DID_EE80_FIHSwVer_ConditionCheckRead: start-on-event=Customer_DID_ConditionCheckRead, operation=DataServices_DID_EE80_FIHSwVer.ConditionCheckRead
        OIT_Customer_DID_ConditionCheckRead_DataServices_DID_EE81_FIHSwReserved0_ConditionCheckRead: start-on-event=Customer_DID_ConditionCheckRead, operation=DataServices_DID_EE81_FIHSwReserved0.ConditionCheckRead
        OIT_Customer_DID_ConditionCheckRead_DataServices_DID_EE82_FIHSwReserved1_ConditionCheckRead: start-on-event=Customer_DID_ConditionCheckRead, operation=DataServices_DID_EE82_FIHSwReserved1.ConditionCheckRead
        OIT_Customer_DID_ConditionCheckRead_DataServices_DID_EE83_FIHSwReserved2_ConditionCheckRead: start-on-event=Customer_DID_ConditionCheckRead, operation=DataServices_DID_EE83_FIHSwReserved2.ConditionCheckRead
        OIT_Customer_DID_ConditionCheckRead_DataServices_DID_EE84_FIHSwReserved3_ConditionCheckRead: start-on-event=Customer_DID_ConditionCheckRead, operation=DataServices_DID_EE84_FIHSwReserved3.ConditionCheckRead
        OIT_Customer_DID_ConditionCheckRead_DataServices_DID_EE85_FIHSwReserved4_ConditionCheckRead: start-on-event=Customer_DID_ConditionCheckRead, operation=DataServices_DID_EE85_FIHSwReserved4.ConditionCheckRead
        OIT_Customer_DID_ConditionCheckRead_DataServices_DID_EE86_FIHSwReserved5_ConditionCheckRead: start-on-event=Customer_DID_ConditionCheckRead, operation=DataServices_DID_EE86_FIHSwReserved5.ConditionCheckRead
        OIT_Customer_DID_ConditionCheckRead_DataServices_DID_EE87_FIHSwReserved6_ConditionCheckRead: start-on-event=Customer_DID_ConditionCheckRead, operation=DataServices_DID_EE87_FIHSwReserved6.ConditionCheckRead
        OIT_Customer_DID_ConditionCheckRead_DataServices_DID_EE88_FIHSwReserved7_ConditionCheckRead: start-on-event=Customer_DID_ConditionCheckRead, operation=DataServices_DID_EE88_FIHSwReserved7.ConditionCheckRead
        OIT_Customer_DID_ConditionCheckRead_DataServices_DID_EED0_SupplierFactoryMode_ConditionCheckRead: start-on-event=Customer_DID_ConditionCheckRead, operation=DataServices_DID_EED0_SupplierFactoryMode.ConditionCheckRead
        OIT_Customer_DID_ConditionCheckRead_DataServices_DID_EED1_SupplierInternalFaultCode_ConditionCheckRead: start-on-event=Customer_DID_ConditionCheckRead, operation=DataServices_DID_EED1_SupplierInternalFaultCode.ConditionCheckRead
        OIT_Customer_DID_ConditionCheckRead_DataServices_DID_EED2_SupplierInternalErrorMemory_ConditionCheckRead: start-on-event=Customer_DID_ConditionCheckRead, operation=DataServices_DID_EED2_SupplierInternalErrorMemory.ConditionCheckRead
        OIT_Customer_DID_ConditionCheckRead_DataServices_DID_F10A_ECU_Cal_Config_Part_Number_ConditionCheckRead: start-on-event=Customer_DID_ConditionCheckRead, operation=DataServices_DID_F10A_ECU_Cal_Config_Part_Number.ConditionCheckRead
        OIT_Customer_DID_ConditionCheckRead_DataServices_DID_F110_Subsystem_Specific_Diagnostic_Specification_Part_Number_Condit337C6607: start-on-event=Customer_DID_ConditionCheckRead, operation=DataServices_DID_F110_Subsystem_Specific_Diagnostic_Specification_Part_Number.ConditionCheckRead
        OIT_Customer_DID_ConditionCheckRead_DataServices_DID_F111_ECU_Core_Assembly_Number_ConditionCheckRead: start-on-event=Customer_DID_ConditionCheckRead, operation=DataServices_DID_F111_ECU_Core_Assembly_Number.ConditionCheckRead
        OIT_Customer_DID_ConditionCheckRead_DataServices_DID_F113_ECU_Delivery_Assembly_Number_ConditionCheckRead: start-on-event=Customer_DID_ConditionCheckRead, operation=DataServices_DID_F113_ECU_Delivery_Assembly_Number.ConditionCheckRead
        OIT_Customer_DID_ConditionCheckRead_DataServices_DID_F124_ECU_Calibration_Data_1_Number_ConditionCheckRead: start-on-event=Customer_DID_ConditionCheckRead, operation=DataServices_DID_F124_ECU_Calibration_Data_1_Number.ConditionCheckRead
        OIT_Customer_DID_ConditionCheckRead_DataServices_DID_F15F_NOS_Generation_Tool_Version_Number_ConditionCheckRead: start-on-event=Customer_DID_ConditionCheckRead, operation=DataServices_DID_F15F_NOS_Generation_Tool_Version_Number.ConditionCheckRead
        OIT_Customer_DID_ConditionCheckRead_DataServices_DID_F162_Software_Download_Specification_Version_ConditionCheckRead: start-on-event=Customer_DID_ConditionCheckRead, operation=DataServices_DID_F162_Software_Download_Specification_Version.ConditionCheckRead
        OIT_Customer_DID_ConditionCheckRead_DataServices_DID_F163_Diagnostic_Specification_Version_ConditionCheckRead: start-on-event=Customer_DID_ConditionCheckRead, operation=DataServices_DID_F163_Diagnostic_Specification_Version.ConditionCheckRead
        OIT_Customer_DID_ConditionCheckRead_DataServices_DID_F166_NOS_Message_Database_1_Version_Number_ConditionCheckRead: start-on-event=Customer_DID_ConditionCheckRead, operation=DataServices_DID_F166_NOS_Message_Database_1_Version_Number.ConditionCheckRead
        OIT_Customer_DID_ConditionCheckRead_DataServices_DID_F17C_NOS_Bootloader_Generation_Tool_Version_Number_ConditionCheckRead: start-on-event=Customer_DID_ConditionCheckRead, operation=DataServices_DID_F17C_NOS_Bootloader_Generation_Tool_Version_Number.ConditionCheckRead
        OIT_Customer_DID_ConditionCheckRead_DataServices_DID_F180_Boot_Software_Identification_ConditionCheckRead: start-on-event=Customer_DID_ConditionCheckRead, operation=DataServices_DID_F180_Boot_Software_Identification.ConditionCheckRead
        OIT_Customer_DID_ConditionCheckRead_DataServices_DID_F188_Vehicle_Manufacturer_ECU_Software_Number_ConditionCheckRead: start-on-event=Customer_DID_ConditionCheckRead, operation=DataServices_DID_F188_Vehicle_Manufacturer_ECU_Software_Number.ConditionCheckRead
        OIT_Customer_DID_ConditionCheckRead_DataServices_DID_F18A_System_Supplier_Identifier_ConditionCheckRead: start-on-event=Customer_DID_ConditionCheckRead, operation=DataServices_DID_F18A_System_Supplier_Identifier.ConditionCheckRead
        OIT_Customer_DID_ConditionCheckRead_DataServices_DID_F18C_ECU_Serial_Number_ConditionCheckRead: start-on-event=Customer_DID_ConditionCheckRead, operation=DataServices_DID_F18C_ECU_Serial_Number.ConditionCheckRead
        OIT_Customer_DID_ConditionCheckRead_DataServices_DID_F190_Vehicle_Identification_Number_ConditionCheckRead: start-on-event=Customer_DID_ConditionCheckRead, operation=DataServices_DID_F190_Vehicle_Identification_Number.ConditionCheckRead
        OIT_DataServices_DID_205A_Torque_Steer_Compensation_Activation_Counter_ReadData_DataServices_DID_205A_Torque_Steer_Compe3770432A: start-on-event=DataServices_DID_205A_Torque_Steer_Compensation_Activation_Counter_ReadData, operation=DataServices_DID_205A_Torque_Steer_Compensation_Activation_Counter.ReadData
        OIT_DataServices_DID_205A_Torque_Steer_Compensation_Activation_Counter_WriteData_DataServices_DID_205A_Torque_Steer_Comp9BB682B2: start-on-event=DataServices_DID_205A_Torque_Steer_Compensation_Activation_Counter_WriteData, operation=DataServices_DID_205A_Torque_Steer_Compensation_Activation_Counter.WriteData
        OIT_DataServices_DID_205B_Brake_Pull_Reduction_Activation_Counter_ReadData_DataServices_DID_205B_Brake_Pull_Reduction_Ac771E8DAB: start-on-event=DataServices_DID_205B_Brake_Pull_Reduction_Activation_Counter_ReadData, operation=DataServices_DID_205B_Brake_Pull_Reduction_Activation_Counter.ReadData
        OIT_DataServices_DID_205B_Brake_Pull_Reduction_Activation_Counter_WriteData_DataServices_DID_205B_Brake_Pull_Reduction_A541DE6E7: start-on-event=DataServices_DID_205B_Brake_Pull_Reduction_Activation_Counter_WriteData, operation=DataServices_DID_205B_Brake_Pull_Reduction_Activation_Counter.WriteData
        OIT_DataServices_DID_3003_Gear_Hardware_Part_Number_ReadData_DataServices_DID_3003_Gear_Hardware_Part_Number_ReadData: start-on-event=DataServices_DID_3003_Gear_Hardware_Part_Number_ReadData, operation=DataServices_DID_3003_Gear_Hardware_Part_Number.ReadData
        OIT_DataServices_DID_3003_Gear_Hardware_Part_Number_WriteData_DataServices_DID_3003_Gear_Hardware_Part_Number_WriteData: start-on-event=DataServices_DID_3003_Gear_Hardware_Part_Number_WriteData, operation=DataServices_DID_3003_Gear_Hardware_Part_Number.WriteData
        OIT_DataServices_DID_301A_Pull_Drift_Compensation_Value_ReadData_DataServices_DID_301A_Pull_Drift_Compensation_Value_ReadData: start-on-event=DataServices_DID_301A_Pull_Drift_Compensation_Value_ReadData, operation=DataServices_DID_301A_Pull_Drift_Compensation_Value.ReadData
        OIT_DataServices_DID_301A_Pull_Drift_Compensation_Value_WriteData_DataServices_DID_301A_Pull_Drift_Compensation_Value_WriteData: start-on-event=DataServices_DID_301A_Pull_Drift_Compensation_Value_WriteData, operation=DataServices_DID_301A_Pull_Drift_Compensation_Value.WriteData
        OIT_DataServices_DID_301F_Steering_Pinion_Rotation_Speed_ReadData_DataServices_DID_301F_Steering_Pinion_Rotation_Speed_ReadData: start-on-event=DataServices_DID_301F_Steering_Pinion_Rotation_Speed_ReadData, operation=DataServices_DID_301F_Steering_Pinion_Rotation_Speed.ReadData
        OIT_DataServices_DID_3020_Steering_Pinion_Angle_ReadData_DataServices_DID_3020_Steering_Pinion_Angle_ReadData: start-on-event=DataServices_DID_3020_Steering_Pinion_Angle_ReadData, operation=DataServices_DID_3020_Steering_Pinion_Angle.ReadData
        OIT_DataServices_DID_330C_Steering_Shaft_Torque_Sensor_2_ReadData_DataServices_DID_330C_Steering_Shaft_Torque_Sensor_2_ReadData: start-on-event=DataServices_DID_330C_Steering_Shaft_Torque_Sensor_2_ReadData, operation=DataServices_DID_330C_Steering_Shaft_Torque_Sensor_2.ReadData
        OIT_DataServices_DID_3B4B_Steering_wheel_angle_alignment_offset_ReadData_DataServices_DID_3B4B_Steering_wheel_angle_alig1BDEB529: start-on-event=DataServices_DID_3B4B_Steering_wheel_angle_alignment_offset_ReadData, operation=DataServices_DID_3B4B_Steering_wheel_angle_alignment_offset.ReadData
        OIT_DataServices_DID_630F_Multiple_VIN_Storage_Original_VIN_ReadData_DataServices_DID_630F_Multiple_VIN_Storage_Original95F09D98: start-on-event=DataServices_DID_630F_Multiple_VIN_Storage_Original_VIN_ReadData, operation=DataServices_DID_630F_Multiple_VIN_Storage_Original_VIN.ReadData
        OIT_DataServices_DID_D100_Active_Diagnostic_Session_ReadData_DataServices_DID_D100_Active_Diagnostic_Session_ReadData: start-on-event=DataServices_DID_D100_Active_Diagnostic_Session_ReadData, operation=DataServices_DID_D100_Active_Diagnostic_Session.ReadData
        OIT_DataServices_DID_D111_ECU_Power_Supply_Voltage_ReadData_DataServices_DID_D111_ECU_Power_Supply_Voltage_ReadData: start-on-event=DataServices_DID_D111_ECU_Power_Supply_Voltage_ReadData, operation=DataServices_DID_D111_ECU_Power_Supply_Voltage.ReadData
        OIT_DataServices_DID_D117_ECU_Internal_Temperature_ReadData_DataServices_DID_D117_ECU_Internal_Temperature_ReadData: start-on-event=DataServices_DID_D117_ECU_Internal_Temperature_ReadData, operation=DataServices_DID_D117_ECU_Internal_Temperature.ReadData
        OIT_DataServices_DID_D118_Motor_Current_ReadData_DataServices_DID_D118_Motor_Current_ReadData: start-on-event=DataServices_DID_D118_Motor_Current_ReadData, operation=DataServices_DID_D118_Motor_Current.ReadData
        OIT_DataServices_DID_DD00_Global_Real_Time_ReadData_DataServices_DID_DD00_Global_Real_Time_ReadData: start-on-event=DataServices_DID_DD00_Global_Real_Time_ReadData, operation=DataServices_DID_DD00_Global_Real_Time.ReadData
        OIT_DataServices_DID_DD01_Total_Distance_ReadData_DataServices_DID_DD01_Total_Distance_ReadData: start-on-event=DataServices_DID_DD01_Total_Distance_ReadData, operation=DataServices_DID_DD01_Total_Distance.ReadData
        OIT_DataServices_DID_DD09_Vehicle_Speed_ReadData_DataServices_DID_DD09_Vehicle_Speed_ReadData: start-on-event=DataServices_DID_DD09_Vehicle_Speed_ReadData, operation=DataServices_DID_DD09_Vehicle_Speed.ReadData
        OIT_DataServices_DID_DE00_VehicleData_ReadData_DataServices_DID_DE00_VehicleData_ReadData: start-on-event=DataServices_DID_DE00_VehicleData_ReadData, operation=DataServices_DID_DE00_VehicleData.ReadData
        OIT_DataServices_DID_DE00_VehicleData_WriteData_DataServices_DID_DE00_VehicleData_WriteData: start-on-event=DataServices_DID_DE00_VehicleData_WriteData, operation=DataServices_DID_DE00_VehicleData.WriteData
        OIT_DataServices_DID_DE01_FIHSwFeatureConfig_ReadData_DataServices_DID_DE01_FIHSwFeatureConfig_ReadData: start-on-event=DataServices_DID_DE01_FIHSwFeatureConfig_ReadData, operation=DataServices_DID_DE01_FIHSwFeatureConfig.ReadData
        OIT_DataServices_DID_DE01_FIHSwFeatureConfig_WriteData_DataServices_DID_DE01_FIHSwFeatureConfig_WriteData: start-on-event=DataServices_DID_DE01_FIHSwFeatureConfig_WriteData, operation=DataServices_DID_DE01_FIHSwFeatureConfig.WriteData
        OIT_DataServices_DID_DE02_FeatureConfig_ReadData_DataServices_DID_DE02_FeatureConfig_ReadData: start-on-event=DataServices_DID_DE02_FeatureConfig_ReadData, operation=DataServices_DID_DE02_FeatureConfig.ReadData
        OIT_DataServices_DID_DE02_FeatureConfig_WriteData_DataServices_DID_DE02_FeatureConfig_WriteData: start-on-event=DataServices_DID_DE02_FeatureConfig_WriteData, operation=DataServices_DID_DE02_FeatureConfig.WriteData
        OIT_DataServices_DID_DE03_Enable_DisableDTCs_ReadData_DataServices_DID_DE03_Enable_DisableDTCs_ReadData: start-on-event=DataServices_DID_DE03_Enable_DisableDTCs_ReadData, operation=DataServices_DID_DE03_Enable_DisableDTCs.ReadData
        OIT_DataServices_DID_DE03_Enable_DisableDTCs_WriteData_DataServices_DID_DE03_Enable_DisableDTCs_WriteData: start-on-event=DataServices_DID_DE03_Enable_DisableDTCs_WriteData, operation=DataServices_DID_DE03_Enable_DisableDTCs.WriteData
        OIT_DataServices_DID_DE04_PDCResetValue_ReadData_DataServices_DID_DE04_PDCResetValue_ReadData: start-on-event=DataServices_DID_DE04_PDCResetValue_ReadData, operation=DataServices_DID_DE04_PDCResetValue.ReadData
        OIT_DataServices_DID_DE04_PDCResetValue_WriteData_DataServices_DID_DE04_PDCResetValue_WriteData: start-on-event=DataServices_DID_DE04_PDCResetValue_WriteData, operation=DataServices_DID_DE04_PDCResetValue.WriteData
        OIT_DataServices_DID_DE05_Unused_ReadData_DataServices_DID_DE05_Unused_ReadData: start-on-event=DataServices_DID_DE05_Unused_ReadData, operation=DataServices_DID_DE05_Unused.ReadData
        OIT_DataServices_DID_DE05_Unused_WriteData_DataServices_DID_DE05_Unused_WriteData: start-on-event=DataServices_DID_DE05_Unused_WriteData, operation=DataServices_DID_DE05_Unused.WriteData
        OIT_DataServices_DID_EE00_DevMessConfig_ReadData_DataServices_DID_EE00_DevMessConfig_ReadData: start-on-event=DataServices_DID_EE00_DevMessConfig_ReadData, operation=DataServices_DID_EE00_DevMessConfig.ReadData
        OIT_DataServices_DID_EE00_DevMessConfig_WriteData_DataServices_DID_EE00_DevMessConfig_WriteData: start-on-event=DataServices_DID_EE00_DevMessConfig_WriteData, operation=DataServices_DID_EE00_DevMessConfig.WriteData
        OIT_DataServices_DID_EE01_XCP_Enable_Disable_ReadData_DataServices_DID_EE01_XCP_Enable_Disable_ReadData: start-on-event=DataServices_DID_EE01_XCP_Enable_Disable_ReadData, operation=DataServices_DID_EE01_XCP_Enable_Disable.ReadData
        OIT_DataServices_DID_EE01_XCP_Enable_Disable_WriteData_DataServices_DID_EE01_XCP_Enable_Disable_WriteData: start-on-event=DataServices_DID_EE01_XCP_Enable_Disable_WriteData, operation=DataServices_DID_EE01_XCP_Enable_Disable.WriteData
        OIT_DataServices_DID_EE02_Assist_On_Off_ReadData_DataServices_DID_EE02_Assist_On_Off_ReadData: start-on-event=DataServices_DID_EE02_Assist_On_Off_ReadData, operation=DataServices_DID_EE02_Assist_On_Off.ReadData
        OIT_DataServices_DID_EE02_Assist_On_Off_WriteData_DataServices_DID_EE02_Assist_On_Off_WriteData: start-on-event=DataServices_DID_EE02_Assist_On_Off_WriteData, operation=DataServices_DID_EE02_Assist_On_Off.WriteData
        OIT_DataServices_DID_EE03_IgnCycleCounter_ReadData_DataServices_DID_EE03_IgnCycleCounter_ReadData: start-on-event=DataServices_DID_EE03_IgnCycleCounter_ReadData, operation=DataServices_DID_EE03_IgnCycleCounter.ReadData
        OIT_DataServices_DID_EE04_IgnOnTime_ReadData_DataServices_DID_EE04_IgnOnTime_ReadData: start-on-event=DataServices_DID_EE04_IgnOnTime_ReadData, operation=DataServices_DID_EE04_IgnOnTime.ReadData
        OIT_DataServices_DID_EE05_FinalMotTq_ReadData_DataServices_DID_EE05_FinalMotTq_ReadData: start-on-event=DataServices_DID_EE05_FinalMotTq_ReadData, operation=DataServices_DID_EE05_FinalMotTq.ReadData
        OIT_DataServices_DID_EE06_VINChanged_ReadData_DataServices_DID_EE06_VINChanged_ReadData: start-on-event=DataServices_DID_EE06_VINChanged_ReadData, operation=DataServices_DID_EE06_VINChanged.ReadData
        OIT_DataServices_DID_EE07_EPSSystemState_ReadData_DataServices_DID_EE07_EPSSystemState_ReadData: start-on-event=DataServices_DID_EE07_EPSSystemState_ReadData, operation=DataServices_DID_EE07_EPSSystemState.ReadData
        OIT_DataServices_DID_EE20_LoAFaultReporting_ReadData_DataServices_DID_EE20_LoAFaultReporting_ReadData: start-on-event=DataServices_DID_EE20_LoAFaultReporting_ReadData, operation=DataServices_DID_EE20_LoAFaultReporting.ReadData
        OIT_DataServices_DID_EE21_CurrentLvlCounter_ReadData_DataServices_DID_EE21_CurrentLvlCounter_ReadData: start-on-event=DataServices_DID_EE21_CurrentLvlCounter_ReadData, operation=DataServices_DID_EE21_CurrentLvlCounter.ReadData
        OIT_DataServices_DID_EE22_VoltageLvlCounters_ReadData_DataServices_DID_EE22_VoltageLvlCounters_ReadData: start-on-event=DataServices_DID_EE22_VoltageLvlCounters_ReadData, operation=DataServices_DID_EE22_VoltageLvlCounters.ReadData
        OIT_DataServices_DID_EE23_TempLvlCounters_ReadData_DataServices_DID_EE23_TempLvlCounters_ReadData: start-on-event=DataServices_DID_EE23_TempLvlCounters_ReadData, operation=DataServices_DID_EE23_TempLvlCounters.ReadData
        OIT_DataServices_DID_EE40_ResearchMessConfig_ReadData_DataServices_DID_EE40_ResearchMessConfig_ReadData: start-on-event=DataServices_DID_EE40_ResearchMessConfig_ReadData, operation=DataServices_DID_EE40_ResearchMessConfig.ReadData
        OIT_DataServices_DID_EE40_ResearchMessConfig_WriteData_DataServices_DID_EE40_ResearchMessConfig_WriteData: start-on-event=DataServices_DID_EE40_ResearchMessConfig_WriteData, operation=DataServices_DID_EE40_ResearchMessConfig.WriteData
        OIT_DataServices_DID_EE41_ResearchFeatureSwitch_ReadData_DataServices_DID_EE41_ResearchFeatureSwitch_ReadData: start-on-event=DataServices_DID_EE41_ResearchFeatureSwitch_ReadData, operation=DataServices_DID_EE41_ResearchFeatureSwitch.ReadData
        OIT_DataServices_DID_EE41_ResearchFeatureSwitch_WriteData_DataServices_DID_EE41_ResearchFeatureSwitch_WriteData: start-on-event=DataServices_DID_EE41_ResearchFeatureSwitch_WriteData, operation=DataServices_DID_EE41_ResearchFeatureSwitch.WriteData
        OIT_DataServices_DID_EE42_ActiveFeatures_ReadData_DataServices_DID_EE42_ActiveFeatures_ReadData: start-on-event=DataServices_DID_EE42_ActiveFeatures_ReadData, operation=DataServices_DID_EE42_ActiveFeatures.ReadData
        OIT_DataServices_DID_EE43_SDMSteeringMode_ReadData_DataServices_DID_EE43_SDMSteeringMode_ReadData: start-on-event=DataServices_DID_EE43_SDMSteeringMode_ReadData, operation=DataServices_DID_EE43_SDMSteeringMode.ReadData
        OIT_DataServices_DID_EE80_FIHSwVer_ReadData_DataServices_DID_EE80_FIHSwVer_ReadData: start-on-event=DataServices_DID_EE80_FIHSwVer_ReadData, operation=DataServices_DID_EE80_FIHSwVer.ReadData
        OIT_DataServices_DID_EE81_FIHSwReserved0_ReadData_DataServices_DID_EE81_FIHSwReserved0_ReadData: start-on-event=DataServices_DID_EE81_FIHSwReserved0_ReadData, operation=DataServices_DID_EE81_FIHSwReserved0.ReadData
        OIT_DataServices_DID_EE81_FIHSwReserved0_WriteData_DataServices_DID_EE81_FIHSwReserved0_WriteData: start-on-event=DataServices_DID_EE81_FIHSwReserved0_WriteData, operation=DataServices_DID_EE81_FIHSwReserved0.WriteData
        OIT_DataServices_DID_EE82_FIHSwReserved1_ReadData_DataServices_DID_EE82_FIHSwReserved1_ReadData: start-on-event=DataServices_DID_EE82_FIHSwReserved1_ReadData, operation=DataServices_DID_EE82_FIHSwReserved1.ReadData
        OIT_DataServices_DID_EE82_FIHSwReserved1_WriteData_DataServices_DID_EE82_FIHSwReserved1_WriteData: start-on-event=DataServices_DID_EE82_FIHSwReserved1_WriteData, operation=DataServices_DID_EE82_FIHSwReserved1.WriteData
        OIT_DataServices_DID_EE83_FIHSwReserved2_ReadData_DataServices_DID_EE83_FIHSwReserved2_ReadData: start-on-event=DataServices_DID_EE83_FIHSwReserved2_ReadData, operation=DataServices_DID_EE83_FIHSwReserved2.ReadData
        OIT_DataServices_DID_EE83_FIHSwReserved2_WriteData_DataServices_DID_EE83_FIHSwReserved2_WriteData: start-on-event=DataServices_DID_EE83_FIHSwReserved2_WriteData, operation=DataServices_DID_EE83_FIHSwReserved2.WriteData
        OIT_DataServices_DID_EE84_FIHSwReserved3_ReadData_DataServices_DID_EE84_FIHSwReserved3_ReadData: start-on-event=DataServices_DID_EE84_FIHSwReserved3_ReadData, operation=DataServices_DID_EE84_FIHSwReserved3.ReadData
        OIT_DataServices_DID_EE84_FIHSwReserved3_WriteData_DataServices_DID_EE84_FIHSwReserved3_WriteData: start-on-event=DataServices_DID_EE84_FIHSwReserved3_WriteData, operation=DataServices_DID_EE84_FIHSwReserved3.WriteData
        OIT_DataServices_DID_EE85_FIHSwReserved4_ReadData_DataServices_DID_EE85_FIHSwReserved4_ReadData: start-on-event=DataServices_DID_EE85_FIHSwReserved4_ReadData, operation=DataServices_DID_EE85_FIHSwReserved4.ReadData
        OIT_DataServices_DID_EE85_FIHSwReserved4_WriteData_DataServices_DID_EE85_FIHSwReserved4_WriteData: start-on-event=DataServices_DID_EE85_FIHSwReserved4_WriteData, operation=DataServices_DID_EE85_FIHSwReserved4.WriteData
        OIT_DataServices_DID_EE86_FIHSwReserved5_ReadData_DataServices_DID_EE86_FIHSwReserved5_ReadData: start-on-event=DataServices_DID_EE86_FIHSwReserved5_ReadData, operation=DataServices_DID_EE86_FIHSwReserved5.ReadData
        OIT_DataServices_DID_EE86_FIHSwReserved5_WriteData_DataServices_DID_EE86_FIHSwReserved5_WriteData: start-on-event=DataServices_DID_EE86_FIHSwReserved5_WriteData, operation=DataServices_DID_EE86_FIHSwReserved5.WriteData
        OIT_DataServices_DID_EE87_FIHSwReserved6_ReadData_DataServices_DID_EE87_FIHSwReserved6_ReadData: start-on-event=DataServices_DID_EE87_FIHSwReserved6_ReadData, operation=DataServices_DID_EE87_FIHSwReserved6.ReadData
        OIT_DataServices_DID_EE87_FIHSwReserved6_WriteData_DataServices_DID_EE87_FIHSwReserved6_WriteData: start-on-event=DataServices_DID_EE87_FIHSwReserved6_WriteData, operation=DataServices_DID_EE87_FIHSwReserved6.WriteData
        OIT_DataServices_DID_EE88_FIHSwReserved7_ReadData_DataServices_DID_EE88_FIHSwReserved7_ReadData: start-on-event=DataServices_DID_EE88_FIHSwReserved7_ReadData, operation=DataServices_DID_EE88_FIHSwReserved7.ReadData
        OIT_DataServices_DID_EE88_FIHSwReserved7_WriteData_DataServices_DID_EE88_FIHSwReserved7_WriteData: start-on-event=DataServices_DID_EE88_FIHSwReserved7_WriteData, operation=DataServices_DID_EE88_FIHSwReserved7.WriteData
        OIT_DataServices_DID_EED0_SupplierFactoryMode_ReadData_DataServices_DID_EED0_SupplierFactoryMode_ReadData: start-on-event=DataServices_DID_EED0_SupplierFactoryMode_ReadData, operation=DataServices_DID_EED0_SupplierFactoryMode.ReadData
        OIT_DataServices_DID_EED0_SupplierFactoryMode_WriteData_DataServices_DID_EED0_SupplierFactoryMode_WriteData: start-on-event=DataServices_DID_EED0_SupplierFactoryMode_WriteData, operation=DataServices_DID_EED0_SupplierFactoryMode.WriteData
        OIT_DataServices_DID_EED1_SupplierInternalFaultCode_ReadData_DataServices_DID_EED1_SupplierInternalFaultCode_ReadData: start-on-event=DataServices_DID_EED1_SupplierInternalFaultCode_ReadData, operation=DataServices_DID_EED1_SupplierInternalFaultCode.ReadData
        OIT_DataServices_DID_EED2_SupplierInternalErrorMemory_ReadData_DataServices_DID_EED2_SupplierInternalErrorMemory_ReadData: start-on-event=DataServices_DID_EED2_SupplierInternalErrorMemory_ReadData, operation=DataServices_DID_EED2_SupplierInternalErrorMemory.ReadData
        OIT_DataServices_DID_F10A_ECU_Cal_Config_Part_Number_ReadData_DataServices_DID_F10A_ECU_Cal_Config_Part_Number_ReadData: start-on-event=DataServices_DID_F10A_ECU_Cal_Config_Part_Number_ReadData, operation=DataServices_DID_F10A_ECU_Cal_Config_Part_Number.ReadData
        OIT_DataServices_DID_F110_Subsystem_Specific_Diagnostic_Specification_Part_Number_ReadData_DataServices_DID_F110_SubsystBEF0AA6C: start-on-event=DataServices_DID_F110_Subsystem_Specific_Diagnostic_Specification_Part_Number_ReadData, operation=DataServices_DID_F110_Subsystem_Specific_Diagnostic_Specification_Part_Number.ReadData
        OIT_DataServices_DID_F110_Subsystem_Specific_Diagnostic_Specification_Part_Number_WriteData_DataServices_DID_F110_Subsys592FEB0E: start-on-event=DataServices_DID_F110_Subsystem_Specific_Diagnostic_Specification_Part_Number_WriteData, operation=DataServices_DID_F110_Subsystem_Specific_Diagnostic_Specification_Part_Number.WriteData
        OIT_DataServices_DID_F111_ECU_Core_Assembly_Number_ReadData_DataServices_DID_F111_ECU_Core_Assembly_Number_ReadData: start-on-event=DataServices_DID_F111_ECU_Core_Assembly_Number_ReadData, operation=DataServices_DID_F111_ECU_Core_Assembly_Number.ReadData
        OIT_DataServices_DID_F111_ECU_Core_Assembly_Number_WriteData_DataServices_DID_F111_ECU_Core_Assembly_Number_WriteData: start-on-event=DataServices_DID_F111_ECU_Core_Assembly_Number_WriteData, operation=DataServices_DID_F111_ECU_Core_Assembly_Number.WriteData
        OIT_DataServices_DID_F113_ECU_Delivery_Assembly_Number_ReadData_DataServices_DID_F113_ECU_Delivery_Assembly_Number_ReadData: start-on-event=DataServices_DID_F113_ECU_Delivery_Assembly_Number_ReadData, operation=DataServices_DID_F113_ECU_Delivery_Assembly_Number.ReadData
        OIT_DataServices_DID_F113_ECU_Delivery_Assembly_Number_WriteData_DataServices_DID_F113_ECU_Delivery_Assembly_Number_WriteData: start-on-event=DataServices_DID_F113_ECU_Delivery_Assembly_Number_WriteData, operation=DataServices_DID_F113_ECU_Delivery_Assembly_Number.WriteData
        OIT_DataServices_DID_F124_ECU_Calibration_Data_1_Number_ReadData_DataServices_DID_F124_ECU_Calibration_Data_1_Number_ReadData: start-on-event=DataServices_DID_F124_ECU_Calibration_Data_1_Number_ReadData, operation=DataServices_DID_F124_ECU_Calibration_Data_1_Number.ReadData
        OIT_DataServices_DID_F15F_NOS_Generation_Tool_Version_Number_ReadData_DataServices_DID_F15F_NOS_Generation_Tool_Version_32A941EF: start-on-event=DataServices_DID_F15F_NOS_Generation_Tool_Version_Number_ReadData, operation=DataServices_DID_F15F_NOS_Generation_Tool_Version_Number.ReadData
        OIT_DataServices_DID_F162_Software_Download_Specification_Version_ReadData_DataServices_DID_F162_Software_Download_SpeciB0BD3564: start-on-event=DataServices_DID_F162_Software_Download_Specification_Version_ReadData, operation=DataServices_DID_F162_Software_Download_Specification_Version.ReadData
        OIT_DataServices_DID_F162_Software_Download_Specification_Version_WriteData_DataServices_DID_F162_Software_Download_Spec1FE5A362: start-on-event=DataServices_DID_F162_Software_Download_Specification_Version_WriteData, operation=DataServices_DID_F162_Software_Download_Specification_Version.WriteData
        OIT_DataServices_DID_F163_Diagnostic_Specification_Version_ReadData_DataServices_DID_F163_Diagnostic_Specification_Versi29A294E5: start-on-event=DataServices_DID_F163_Diagnostic_Specification_Version_ReadData, operation=DataServices_DID_F163_Diagnostic_Specification_Version.ReadData
        OIT_DataServices_DID_F163_Diagnostic_Specification_Version_WriteData_DataServices_DID_F163_Diagnostic_Specification_Vers68AC08FA: start-on-event=DataServices_DID_F163_Diagnostic_Specification_Version_WriteData, operation=DataServices_DID_F163_Diagnostic_Specification_Version.WriteData
        OIT_DataServices_DID_F166_NOS_Message_Database_1_Version_Number_ReadData_DataServices_DID_F166_NOS_Message_Database_1_Ve1E71D252: start-on-event=DataServices_DID_F166_NOS_Message_Database_1_Version_Number_ReadData, operation=DataServices_DID_F166_NOS_Message_Database_1_Version_Number.ReadData
        OIT_DataServices_DID_F166_NOS_Message_Database_1_Version_Number_WriteData_DataServices_DID_F166_NOS_Message_Database_1_V0EE595F5: start-on-event=DataServices_DID_F166_NOS_Message_Database_1_Version_Number_WriteData, operation=DataServices_DID_F166_NOS_Message_Database_1_Version_Number.WriteData
        OIT_DataServices_DID_F17C_NOS_Bootloader_Generation_Tool_Version_Number_ReadData_DataServices_DID_F17C_NOS_Bootloader_Ge16F05456: start-on-event=DataServices_DID_F17C_NOS_Bootloader_Generation_Tool_Version_Number_ReadData, operation=DataServices_DID_F17C_NOS_Bootloader_Generation_Tool_Version_Number.ReadData
        OIT_DataServices_DID_F180_Boot_Software_Identification_ReadData_DataServices_DID_F180_Boot_Software_Identification_ReadData: start-on-event=DataServices_DID_F180_Boot_Software_Identification_ReadData, operation=DataServices_DID_F180_Boot_Software_Identification.ReadData
        OIT_DataServices_DID_F188_Vehicle_Manufacturer_ECU_Software_Number_ReadData_DataServices_DID_F188_Vehicle_Manufacturer_E3D2785DD: start-on-event=DataServices_DID_F188_Vehicle_Manufacturer_ECU_Software_Number_ReadData, operation=DataServices_DID_F188_Vehicle_Manufacturer_ECU_Software_Number.ReadData
        OIT_DataServices_DID_F18A_System_Supplier_Identifier_ReadData_DataServices_DID_F18A_System_Supplier_Identifier_ReadData: start-on-event=DataServices_DID_F18A_System_Supplier_Identifier_ReadData, operation=DataServices_DID_F18A_System_Supplier_Identifier.ReadData
        OIT_DataServices_DID_F18A_System_Supplier_Identifier_WriteData_DataServices_DID_F18A_System_Supplier_Identifier_WriteData: start-on-event=DataServices_DID_F18A_System_Supplier_Identifier_WriteData, operation=DataServices_DID_F18A_System_Supplier_Identifier.WriteData
        OIT_DataServices_DID_F18C_ECU_Serial_Number_ReadData_DataServices_DID_F18C_ECU_Serial_Number_ReadData: start-on-event=DataServices_DID_F18C_ECU_Serial_Number_ReadData, operation=DataServices_DID_F18C_ECU_Serial_Number.ReadData
        OIT_DataServices_DID_F18C_ECU_Serial_Number_WriteData_DataServices_DID_F18C_ECU_Serial_Number_WriteData: start-on-event=DataServices_DID_F18C_ECU_Serial_Number_WriteData, operation=DataServices_DID_F18C_ECU_Serial_Number.WriteData
        OIT_DataServices_DID_F190_Vehicle_Identification_Number_ReadData_DataServices_DID_F190_Vehicle_Identification_Number_ReadData: start-on-event=DataServices_DID_F190_Vehicle_Identification_Number_ReadData, operation=DataServices_DID_F190_Vehicle_Identification_Number.ReadData
        OIT_RoutineServices_RTN_0202_On_Demand_Self_Test_RequestResults_RoutineServices_RTN_0202_On_Demand_Self_Test_RequestResults: start-on-event=RoutineServices_RTN_0202_On_Demand_Self_Test_RequestResults, operation=RoutineServices_RTN_0202_On_Demand_Self_Test.RequestResults
        OIT_RoutineServices_RTN_0202_On_Demand_Self_Test_Start_RoutineServices_RTN_0202_On_Demand_Self_Test_Start: start-on-event=RoutineServices_RTN_0202_On_Demand_Self_Test_Start, operation=RoutineServices_RTN_0202_On_Demand_Self_Test.Start
        OIT_RoutineServices_RTN_0202_On_Demand_Self_Test_Stop_RoutineServices_RTN_0202_On_Demand_Self_Test_Stop: start-on-event=RoutineServices_RTN_0202_On_Demand_Self_Test_Stop, operation=RoutineServices_RTN_0202_On_Demand_Self_Test.Stop
        OIT_RoutineServices_RTN_200E_Calibrate_Steering_Angle_Centre_Position_Start_RoutineServices_RTN_200E_Calibrate_Steering_64FDD7E3: start-on-event=RoutineServices_RTN_200E_Calibrate_Steering_Angle_Centre_Position_Start, operation=RoutineServices_RTN_200E_Calibrate_Steering_Angle_Centre_Position.Start
        OIT_RoutineServices_RTN_200F_Clear_Steering_Angle_Centre_Position_Calibration_Start_RoutineServices_RTN_200F_Clear_Steer7D11CAD1: start-on-event=RoutineServices_RTN_200F_Clear_Steering_Angle_Centre_Position_Calibration_Start, operation=RoutineServices_RTN_200F_Clear_Steering_Angle_Centre_Position_Calibration.Start
        OIT_RoutineServices_RTN_DC00_Reset_Assist_Fault_Counters_Start_RoutineServices_RTN_DC00_Reset_Assist_Fault_Counters_Start: start-on-event=RoutineServices_RTN_DC00_Reset_Assist_Fault_Counters_Start, operation=RoutineServices_RTN_DC00_Reset_Assist_Fault_Counters.Start
        OIT_ServiceRequestNotification_Confirmation_ServiceRequestNotification_Confirmation: start-on-event=ServiceRequestNotification_Confirmation, operation=ServiceRequestNotification.Confirmation
        OIT_ServiceRequestNotification_Indication_ServiceRequestNotification_Indication: start-on-event=ServiceRequestNotification_Indication, operation=ServiceRequestNotification.Indication
      port-api-options:
        enable-take-address=false, indirect-api=false, port=BswM_MSI_BswMEcuResetMod
        enable-take-address=false, indirect-api=false, port=ClrAllDiagc
        enable-take-address=false, indirect-api=false, port=ClrDiagcReq
        enable-take-address=false, indirect-api=false, port=ClrLtchCntrData
        enable-take-address=false, indirect-api=false, port=CustXcpEna
        enable-take-address=false, indirect-api=false, port=DataServices_DID_205A_Torque_Steer_Compensation_Activation_Counter
        enable-take-address=false, indirect-api=false, port=DataServices_DID_205B_Brake_Pull_Reduction_Activation_Counter
        enable-take-address=false, indirect-api=false, port=DataServices_DID_3003_Gear_Hardware_Part_Number
        enable-take-address=false, indirect-api=false, port=DataServices_DID_301A_Pull_Drift_Compensation_Value
        enable-take-address=false, indirect-api=false, port=DataServices_DID_301F_Steering_Pinion_Rotation_Speed
        enable-take-address=false, indirect-api=false, port=DataServices_DID_3020_Steering_Pinion_Angle
        enable-take-address=false, indirect-api=false, port=DataServices_DID_330C_Steering_Shaft_Torque_Sensor_2
        enable-take-address=false, indirect-api=false, port=DataServices_DID_3B4B_Steering_wheel_angle_alignment_offset
        enable-take-address=false, indirect-api=false, port=DataServices_DID_630F_Multiple_VIN_Storage_Original_VIN
        enable-take-address=false, indirect-api=false, port=DataServices_DID_D100_Active_Diagnostic_Session
        enable-take-address=false, indirect-api=false, port=DataServices_DID_D111_ECU_Power_Supply_Voltage
        enable-take-address=false, indirect-api=false, port=DataServices_DID_D117_ECU_Internal_Temperature
        enable-take-address=false, indirect-api=false, port=DataServices_DID_D118_Motor_Current
        enable-take-address=false, indirect-api=false, port=DataServices_DID_DD00_Global_Real_Time
        enable-take-address=false, indirect-api=false, port=DataServices_DID_DD01_Total_Distance
        enable-take-address=false, indirect-api=false, port=DataServices_DID_DD09_Vehicle_Speed
        enable-take-address=false, indirect-api=false, port=DataServices_DID_DE00_VehicleData
        enable-take-address=false, indirect-api=false, port=DataServices_DID_DE01_FIHSwFeatureConfig
        enable-take-address=false, indirect-api=false, port=DataServices_DID_DE02_FeatureConfig
        enable-take-address=false, indirect-api=false, port=DataServices_DID_DE03_Enable_DisableDTCs
        enable-take-address=false, indirect-api=false, port=DataServices_DID_DE04_PDCResetValue
        enable-take-address=false, indirect-api=false, port=DataServices_DID_DE05_Unused
        enable-take-address=false, indirect-api=false, port=DataServices_DID_EE00_DevMessConfig
        enable-take-address=false, indirect-api=false, port=DataServices_DID_EE01_XCP_Enable_Disable
        enable-take-address=false, indirect-api=false, port=DataServices_DID_EE02_Assist_On_Off
        enable-take-address=false, indirect-api=false, port=DataServices_DID_EE03_IgnCycleCounter
        enable-take-address=false, indirect-api=false, port=DataServices_DID_EE04_IgnOnTime
        enable-take-address=false, indirect-api=false, port=DataServices_DID_EE05_FinalMotTq
        enable-take-address=false, indirect-api=false, port=DataServices_DID_EE06_VINChanged
        enable-take-address=false, indirect-api=false, port=DataServices_DID_EE07_EPSSystemState
        enable-take-address=false, indirect-api=false, port=DataServices_DID_EE20_LoAFaultReporting
        enable-take-address=false, indirect-api=false, port=DataServices_DID_EE21_CurrentLvlCounter
        enable-take-address=false, indirect-api=false, port=DataServices_DID_EE22_VoltageLvlCounters
        enable-take-address=false, indirect-api=false, port=DataServices_DID_EE23_TempLvlCounters
        enable-take-address=false, indirect-api=false, port=DataServices_DID_EE40_ResearchMessConfig
        enable-take-address=false, indirect-api=false, port=DataServices_DID_EE41_ResearchFeatureSwitch
        enable-take-address=false, indirect-api=false, port=DataServices_DID_EE42_ActiveFeatures
        enable-take-address=false, indirect-api=false, port=DataServices_DID_EE43_SDMSteeringMode
        enable-take-address=false, indirect-api=false, port=DataServices_DID_EE80_FIHSwVer
        enable-take-address=false, indirect-api=false, port=DataServices_DID_EE81_FIHSwReserved0
        enable-take-address=false, indirect-api=false, port=DataServices_DID_EE82_FIHSwReserved1
        enable-take-address=false, indirect-api=false, port=DataServices_DID_EE83_FIHSwReserved2
        enable-take-address=false, indirect-api=false, port=DataServices_DID_EE84_FIHSwReserved3
        enable-take-address=false, indirect-api=false, port=DataServices_DID_EE85_FIHSwReserved4
        enable-take-address=false, indirect-api=false, port=DataServices_DID_EE86_FIHSwReserved5
        enable-take-address=false, indirect-api=false, port=DataServices_DID_EE87_FIHSwReserved6
        enable-take-address=false, indirect-api=false, port=DataServices_DID_EE88_FIHSwReserved7
        enable-take-address=false, indirect-api=false, port=DataServices_DID_EED0_SupplierFactoryMode
        enable-take-address=false, indirect-api=false, port=DataServices_DID_EED1_SupplierInternalFaultCode
        enable-take-address=false, indirect-api=false, port=DataServices_DID_EED2_SupplierInternalErrorMemory
        enable-take-address=false, indirect-api=false, port=DataServices_DID_F10A_ECU_Cal_Config_Part_Number
        enable-take-address=false, indirect-api=false, port=DataServices_DID_F110_Subsystem_Specific_Diagnostic_Specification_Part_Number
        enable-take-address=false, indirect-api=false, port=DataServices_DID_F111_ECU_Core_Assembly_Number
        enable-take-address=false, indirect-api=false, port=DataServices_DID_F113_ECU_Delivery_Assembly_Number
        enable-take-address=false, indirect-api=false, port=DataServices_DID_F124_ECU_Calibration_Data_1_Number
        enable-take-address=false, indirect-api=false, port=DataServices_DID_F15F_NOS_Generation_Tool_Version_Number
        enable-take-address=false, indirect-api=false, port=DataServices_DID_F162_Software_Download_Specification_Version
        enable-take-address=false, indirect-api=false, port=DataServices_DID_F163_Diagnostic_Specification_Version
        enable-take-address=false, indirect-api=false, port=DataServices_DID_F166_NOS_Message_Database_1_Version_Number
        enable-take-address=false, indirect-api=false, port=DataServices_DID_F17C_NOS_Bootloader_Generation_Tool_Version_Number
        enable-take-address=false, indirect-api=false, port=DataServices_DID_F180_Boot_Software_Identification
        enable-take-address=false, indirect-api=false, port=DataServices_DID_F188_Vehicle_Manufacturer_ECU_Software_Number
        enable-take-address=false, indirect-api=false, port=DataServices_DID_F18A_System_Supplier_Identifier
        enable-take-address=false, indirect-api=false, port=DataServices_DID_F18C_ECU_Serial_Number
        enable-take-address=false, indirect-api=false, port=DataServices_DID_F190_Vehicle_Identification_Number
        enable-take-address=false, indirect-api=false, port=Did205A
        enable-take-address=false, indirect-api=false, port=Did205B
        enable-take-address=false, indirect-api=false, port=Did3003
        enable-take-address=false, indirect-api=false, port=Did301A
        enable-take-address=false, indirect-api=false, port=Did630F
        enable-take-address=false, indirect-api=false, port=Did630FChk
        enable-take-address=false, indirect-api=false, port=DidDE{00..05}
        enable-take-address=false, indirect-api=false, port=DidEE{00..02}
        enable-take-address=false, indirect-api=false, port=DidEE{21..23}
        enable-take-address=false, indirect-api=false, port=DidEE40
        enable-take-address=false, indirect-api=false, port=DidEE41
        enable-take-address=false, indirect-api=false, port=DidEE{81..88}
        enable-take-address=false, indirect-api=false, port=DidEED0
        enable-take-address=false, indirect-api=false, port=DidF110
        enable-take-address=false, indirect-api=false, port=DidF111
        enable-take-address=false, indirect-api=false, port=DidF113
        enable-take-address=false, indirect-api=false, port=DidF15F
        enable-take-address=false, indirect-api=false, port=DidF162
        enable-take-address=false, indirect-api=false, port=DidF163
        enable-take-address=false, indirect-api=false, port=DidF166
        enable-take-address=false, indirect-api=false, port=DidF18A
        enable-take-address=false, indirect-api=false, port=DidF18C
        enable-take-address=false, indirect-api=false, port=DidF190
        enable-take-address=false, indirect-api=false, port=EcuId
        enable-take-address=false, indirect-api=false, port=EcuTFild
        enable-take-address=false, indirect-api=false, port=FordAbsPrsnt
        enable-take-address=false, indirect-api=false, port=FordActvNiblCtrlEnad
        enable-take-address=false, indirect-api=false, port=FordActvParkAssiEnad
        enable-take-address=false, indirect-api=false, port=FordActvRtnEnad
        enable-take-address=false, indirect-api=false, port=FordAfsEquid
        enable-take-address=false, indirect-api=false, port=FordAppldFinalMotTq
        enable-take-address=false, indirect-api=false, port=FordBrkPlsRejctnEnad
        enable-take-address=false, indirect-api=false, port=FordCmpdHwPosn
        enable-take-address=false, indirect-api=false, port=FordDrvrSteerRcmdnEnad
        enable-take-address=false, indirect-api=false, port=FordEngTqClass
        enable-take-address=false, indirect-api=false, port=FordEpsCurr
        enable-take-address=false, indirect-api=false, port=FordEpsLifeCycMod
        enable-take-address=false, indirect-api=false, port=FordEpsSysSt
        enable-take-address=false, indirect-api=false, port=FordEpsVltg
        enable-take-address=false, indirect-api=false, port=FordEscPrsnt
        enable-take-address=false, indirect-api=false, port=FordEvasSteerAssiEnad
        enable-take-address=false, indirect-api=false, port=FordInpTqRaw
        enable-take-address=false, indirect-api=false, port=FordLaneCentrAssiEnad
        enable-take-address=false, indirect-api=false, port=FordLaneDprtrWarnEnad
        enable-take-address=false, indirect-api=false, port=FordLaneKeepAssiEnad
        enable-take-address=false, indirect-api=false, port=FordMaxBattCurr
        enable-take-address=false, indirect-api=false, port=FordMinBattVltg
        enable-take-address=false, indirect-api=false, port=FordPullDriftCmpEnad
        enable-take-address=false, indirect-api=false, port=FordResrchFctEnad
        enable-take-address=false, indirect-api=false, port=FordSelDrvModEnad
        enable-take-address=false, indirect-api=false, port=FordSoftEndStopEnad
        enable-take-address=false, indirect-api=false, port=FordSrvPullDriftCmpRstVal
        enable-take-address=false, indirect-api=false, port=FordStrtStopSt
        enable-take-address=false, indirect-api=false, port=FordTqSteerCmpEnad
        enable-take-address=false, indirect-api=false, port=FordTrfcJamAssiEnad
        enable-take-address=false, indirect-api=false, port=FordTrlrBackupAssi5WhlEnad
        enable-take-address=false, indirect-api=false, port=FordTrlrBackupAssiEnad
        enable-take-address=false, indirect-api=false, port=FordTrlrBackupAssiTrigEnad
        enable-take-address=false, indirect-api=false, port=FordVehGlbRealTi
        enable-take-address=false, indirect-api=false, port=FordVehIdnNr
        enable-take-address=false, indirect-api=false, port=FordVehOdom
        enable-take-address=false, indirect-api=false, port=FordVehSpdLoQly
        enable-take-address=false, indirect-api=false, port=FordVehSpdLoQlyVld
        enable-take-address=false, indirect-api=false, port=FordVehSteerPinionAgOffs
        enable-take-address=false, indirect-api=false, port=GetRefTmr100MicroSec32bit
        enable-take-address=false, indirect-api=false, port=GetSigImcData_logl
        enable-take-address=false, indirect-api=false, port=GetSigImcData_u08
        enable-take-address=false, indirect-api=false, port=HwVelToSerlCom
        enable-take-address=false, indirect-api=false, port=IgnCntr
        enable-take-address=false, indirect-api=false, port=MotCurrQax
        enable-take-address=false, indirect-api=false, port=NxtrCalIdsCal0DevlpDesc
        enable-take-address=false, indirect-api=false, port=NxtrCalIdsCal1DevlpDesc
        enable-take-address=false, indirect-api=false, port=RoutineServices_RTN_0202_On_Demand_Self_Test
        enable-take-address=false, indirect-api=false, port=RoutineServices_RTN_200E_Calibrate_Steering_Angle_Centre_Position
        enable-take-address=false, indirect-api=false, port=RoutineServices_RTN_200F_Clear_Steering_Angle_Centre_Position_Calibration
        enable-take-address=false, indirect-api=false, port=RoutineServices_RTN_DC00_Reset_Assist_Fault_Counters
        enable-take-address=false, indirect-api=false, port=RstReq
        enable-take-address=false, indirect-api=false, port=RtnDC00Req
        enable-take-address=false, indirect-api=false, port=ServiceRequestNotification
        enable-take-address=false, indirect-api=false, port=SetNtcSts
        enable-take-address=false, indirect-api=false, port=VehSpd
      110 x runnable:
        CustDiagInit1
          data-receive-point-by-arguments:
            21 x access:
              REC_EcuId_Val: accessed-variable=EcuId.Val
              REC_EcuTFild_Val: accessed-variable=EcuTFild.Val
              REC_FordAppldFinalMotTq_Val_1: accessed-variable=FordAppldFinalMotTq.Val
              REC_FordCmpdHwPosn_Val: accessed-variable=FordCmpdHwPosn.Val
              REC_FordEpsCurr_Val: accessed-variable=FordEpsCurr.Val
              REC_FordEpsLifeCycMod_Val: accessed-variable=FordEpsLifeCycMod.Val
              REC_FordEpsSysSt_Val: accessed-variable=FordEpsSysSt.Val
              REC_FordEpsVltg_Val: accessed-variable=FordEpsVltg.Val
              REC_FordInpTqRaw_Val_1: accessed-variable=FordInpTqRaw.Val
              REC_FordMaxBattCurr_Val: accessed-variable=FordMaxBattCurr.Val
              REC_FordMinBattVltg_Val: accessed-variable=FordMinBattVltg.Val
              REC_FordVehGlbRealTi_Val: accessed-variable=FordVehGlbRealTi.Val
              REC_FordVehIdnNr_Ary1D: accessed-variable=FordVehIdnNr.Ary1D
              REC_FordVehOdom_Val: accessed-variable=FordVehOdom.Val
              REC_FordVehSpdLoQly_Val: accessed-variable=FordVehSpdLoQly.Val
              REC_FordVehSpdLoQlyVld_Logl: accessed-variable=FordVehSpdLoQlyVld.Logl
              REC_FordVehSteerPinionAgOffs_Val: accessed-variable=FordVehSteerPinionAgOffs.Val
              REC_HwVelToSerlCom_Val: accessed-variable=HwVelToSerlCom.Val
              REC_IgnCntr_Val: accessed-variable=IgnCntr.Val
              REC_MotCurrQax_Val: accessed-variable=MotCurrQax.Val
              REC_VehSpd_Val: accessed-variable=VehSpd.Val
          data-send-points:
            4 x access:
              SEND_ClrDiagcReq_Val: accessed-variable=ClrDiagcReq.Val
              SEND_CustXcpEna_Logl: accessed-variable=CustXcpEna.Logl
              SEND_RstReq_Val: accessed-variable=RstReq.Val
              SEND_RtnDC00Req_Val: accessed-variable=RtnDC00Req.Val
          82 x sync call, all with timeout=0:
            SC_ClrAllDiagc_Oper: operation=ClrAllDiagc.Oper
            SC_ClrLtchCntrData_Oper: operation=ClrLtchCntrData.Oper
            SC_Did205A_GetErrorStatus: operation=Did205A.GetErrorStatus
            SC_Did205A_SetRamBlockStatus: operation=Did205A.SetRamBlockStatus
            SC_Did205B_GetErrorStatus: operation=Did205B.GetErrorStatus
            SC_Did205B_SetRamBlockStatus: operation=Did205B.SetRamBlockStatus
            SC_Did3003_GetErrorStatus: operation=Did3003.GetErrorStatus
            SC_Did3003_SetRamBlockStatus: operation=Did3003.SetRamBlockStatus
            SC_Did301A_GetErrorStatus: operation=Did301A.GetErrorStatus
            SC_Did301A_SetRamBlockStatus: operation=Did301A.SetRamBlockStatus
            SC_Did630F_GetErrorStatus: operation=Did630F.GetErrorStatus
            SC_Did630F_SetRamBlockStatus: operation=Did630F.SetRamBlockStatus
            SC_Did630FChk_GetErrorStatus: operation=Did630FChk.GetErrorStatus
            SC_Did630FChk_SetRamBlockStatus: operation=Did630FChk.SetRamBlockStatus
            SC_DidDE00_GetErrorStatus: operation=DidDE00.GetErrorStatus
            SC_DidDE00_SetRamBlockStatus: operation=DidDE00.SetRamBlockStatus
            SC_DidDE01_GetErrorStatus: operation=DidDE01.GetErrorStatus
            SC_DidDE01_SetRamBlockStatus: operation=DidDE01.SetRamBlockStatus
            SC_DidDE02_GetErrorStatus: operation=DidDE02.GetErrorStatus
            SC_DidDE02_SetRamBlockStatus: operation=DidDE02.SetRamBlockStatus
            SC_DidDE03_GetErrorStatus: operation=DidDE03.GetErrorStatus
            SC_DidDE03_SetRamBlockStatus: operation=DidDE03.SetRamBlockStatus
            SC_DidDE04_GetErrorStatus: operation=DidDE04.GetErrorStatus
            SC_DidDE04_SetRamBlockStatus: operation=DidDE04.SetRamBlockStatus
            SC_DidDE05_GetErrorStatus: operation=DidDE05.GetErrorStatus
            SC_DidDE05_SetRamBlockStatus: operation=DidDE05.SetRamBlockStatus
            SC_DidEE00_GetErrorStatus: operation=DidEE00.GetErrorStatus
            SC_DidEE00_SetRamBlockStatus: operation=DidEE00.SetRamBlockStatus
            SC_DidEE01_GetErrorStatus: operation=DidEE01.GetErrorStatus
            SC_DidEE01_SetRamBlockStatus: operation=DidEE01.SetRamBlockStatus
            SC_DidEE02_GetErrorStatus: operation=DidEE02.GetErrorStatus
            SC_DidEE02_SetRamBlockStatus: operation=DidEE02.SetRamBlockStatus
            SC_DidEE21_GetErrorStatus: operation=DidEE21.GetErrorStatus
            SC_DidEE21_SetRamBlockStatus: operation=DidEE21.SetRamBlockStatus
            SC_DidEE22_GetErrorStatus: operation=DidEE22.GetErrorStatus
            SC_DidEE22_SetRamBlockStatus: operation=DidEE22.SetRamBlockStatus
            SC_DidEE23_GetErrorStatus: operation=DidEE23.GetErrorStatus
            SC_DidEE23_SetRamBlockStatus: operation=DidEE23.SetRamBlockStatus
            SC_DidEE40_GetErrorStatus: operation=DidEE40.GetErrorStatus
            SC_DidEE40_SetRamBlockStatus: operation=DidEE40.SetRamBlockStatus
            SC_DidEE41_GetErrorStatus: operation=DidEE41.GetErrorStatus
            SC_DidEE41_SetRamBlockStatus: operation=DidEE41.SetRamBlockStatus
            SC_DidEE81_GetErrorStatus: operation=DidEE81.GetErrorStatus
            SC_DidEE81_SetRamBlockStatus: operation=DidEE81.SetRamBlockStatus
            SC_DidEE82_GetErrorStatus: operation=DidEE82.GetErrorStatus
            SC_DidEE82_SetRamBlockStatus: operation=DidEE82.SetRamBlockStatus
            SC_DidEE83_GetErrorStatus: operation=DidEE83.GetErrorStatus
            SC_DidEE83_SetRamBlockStatus: operation=DidEE83.SetRamBlockStatus
            SC_DidEE84_GetErrorStatus: operation=DidEE84.GetErrorStatus
            SC_DidEE84_SetRamBlockStatus: operation=DidEE84.SetRamBlockStatus
            SC_DidEE85_GetErrorStatus: operation=DidEE85.GetErrorStatus
            SC_DidEE85_SetRamBlockStatus: operation=DidEE85.SetRamBlockStatus
            SC_DidEE86_GetErrorStatus: operation=DidEE86.GetErrorStatus
            SC_DidEE86_SetRamBlockStatus: operation=DidEE86.SetRamBlockStatus
            SC_DidEE87_GetErrorStatus: operation=DidEE87.GetErrorStatus
            SC_DidEE87_SetRamBlockStatus: operation=DidEE87.SetRamBlockStatus
            SC_DidEE88_GetErrorStatus: operation=DidEE88.GetErrorStatus
            SC_DidEE88_SetRamBlockStatus: operation=DidEE88.SetRamBlockStatus
            SC_DidEED0_GetErrorStatus: operation=DidEED0.GetErrorStatus
            SC_DidEED0_SetRamBlockStatus: operation=DidEED0.SetRamBlockStatus
            SC_DidF110_GetErrorStatus: operation=DidF110.GetErrorStatus
            SC_DidF110_SetRamBlockStatus: operation=DidF110.SetRamBlockStatus
            SC_DidF111_GetErrorStatus: operation=DidF111.GetErrorStatus
            SC_DidF111_SetRamBlockStatus: operation=DidF111.SetRamBlockStatus
            SC_DidF113_GetErrorStatus: operation=DidF113.GetErrorStatus
            SC_DidF113_SetRamBlockStatus: operation=DidF113.SetRamBlockStatus
            SC_DidF15F_GetErrorStatus: operation=DidF15F.GetErrorStatus
            SC_DidF15F_SetRamBlockStatus: operation=DidF15F.SetRamBlockStatus
            SC_DidF162_GetErrorStatus: operation=DidF162.GetErrorStatus
            SC_DidF162_SetRamBlockStatus: operation=DidF162.SetRamBlockStatus
            SC_DidF163_GetErrorStatus: operation=DidF163.GetErrorStatus
            SC_DidF163_SetRamBlockStatus: operation=DidF163.SetRamBlockStatus
            SC_DidF166_GetErrorStatus: operation=DidF166.GetErrorStatus
            SC_DidF166_SetRamBlockStatus: operation=DidF166.SetRamBlockStatus
            SC_DidF18A_GetErrorStatus: operation=DidF18A.GetErrorStatus
            SC_DidF18A_SetRamBlockStatus: operation=DidF18A.SetRamBlockStatus
            SC_DidF18C_GetErrorStatus: operation=DidF18C.GetErrorStatus
            SC_DidF18C_SetRamBlockStatus: operation=DidF18C.SetRamBlockStatus
            SC_DidF190_GetErrorStatus: operation=DidF190.GetErrorStatus
            SC_DidF190_SetRamBlockStatus: operation=DidF190.SetRamBlockStatus
            SC_GetRefTmr100MicroSec32bit_Oper: operation=GetRefTmr100MicroSec32bit.Oper
            SC_SetNtcSts_Oper: operation=SetNtcSts.Oper
        CustDiagPer1
          data-receive-point-by-arguments:
            access REC_EcuTFild_Val: accessed-variable=EcuTFild.Val
            access REC_FordEpsCurr_Val: accessed-variable=FordEpsCurr.Val
            access REC_FordEpsVltg_Val: accessed-variable=FordEpsVltg.Val
        CustDiagPer2: mode-access-point=BswM_MSI_BswMEcuResetMod.BswM_MDGP_BswMEcuResetMod
          mode switch point SWITCH_BswM_MSI_BswMEcuResetMod_BswM_MDGP_BswMEcuResetMod: mode-group=BswM_MSI_BswMEcuResetMod.BswM_MDGP_BswMEcuResetMod
          sync call SC_GetSigImcData_logl_Oper: operation=GetSigImcData_logl.Oper, timeout=0
          sync call SC_GetSigImcData_u08_Oper: operation=GetSigImcData_u08.Oper, timeout=0
        CustDiagPer3
          data-receive-point-by-arguments:
            access REC_FordVehIdnNr_Ary1D: accessed-variable=FordVehIdnNr.Ary1D
          data-send-points:
            24 x access:
              SEND_FordAbsPrsnt_Logl: accessed-variable=FordAbsPrsnt.Logl
              SEND_FordActvNiblCtrlEnad_Logl: accessed-variable=FordActvNiblCtrlEnad.Logl
              SEND_FordActvParkAssiEnad_Logl: accessed-variable=FordActvParkAssiEnad.Logl
              SEND_FordActvRtnEnad_Logl: accessed-variable=FordActvRtnEnad.Logl
              SEND_FordAfsEquid_Logl: accessed-variable=FordAfsEquid.Logl
              SEND_FordBrkOscnRednEnad_Logl: accessed-variable=FordBrkPlsRejctnEnad.Logl
              SEND_FordDrvrSteerRecomEnad_Logl: accessed-variable=FordDrvrSteerRcmdnEnad.Logl
              SEND_FordEngTqClass_Val: accessed-variable=FordEngTqClass.Val
              SEND_FordEscPrsnt_Logl: accessed-variable=FordEscPrsnt.Logl
              SEND_FordEvasSteerAssiEnad_Logl: accessed-variable=FordEvasSteerAssiEnad.Logl
              SEND_FordLaneCentrAssiEnad_Logl: accessed-variable=FordLaneCentrAssiEnad.Logl
              SEND_FordLaneDprtrWarnEnad_Logl: accessed-variable=FordLaneDprtrWarnEnad.Logl
              SEND_FordLaneKeepAssiEnad_Logl: accessed-variable=FordLaneKeepAssiEnad.Logl
              SEND_FordPullDriftCompEnad_Logl: accessed-variable=FordPullDriftCmpEnad.Logl
              SEND_FordResrchFctEnad_Logl: accessed-variable=FordResrchFctEnad.Logl
              SEND_FordSelDrvModEnad_Logl: accessed-variable=FordSelDrvModEnad.Logl
              SEND_FordSoftEndStopEnad_Logl: accessed-variable=FordSoftEndStopEnad.Logl
              SEND_FordSrvPullDriftCmpRstVal_Val: accessed-variable=FordSrvPullDriftCmpRstVal.Val
              SEND_FordStrtStopSt_Val: accessed-variable=FordStrtStopSt.Val
              SEND_FordTqSteerCmpEnad_Logl: accessed-variable=FordTqSteerCmpEnad.Logl
              SEND_FordTrfcJamAssiEnad_Logl: accessed-variable=FordTrfcJamAssiEnad.Logl
              SEND_FordTrlrBackupAssi5WhlEnad_Logl: accessed-variable=FordTrlrBackupAssi5WhlEnad.Logl
              SEND_FordTrlrBackupAssiEnad_Logl: accessed-variable=FordTrlrBackupAssiEnad.Logl
              SEND_FordTrlrBackupAssiTrigEnad_Logl: accessed-variable=FordTrlrBackupAssiTrigEnad.Logl
          sync call SC_GetSigImcData_logl_Oper: operation=GetSigImcData_logl.Oper, timeout=0
          sync call SC_GetSigImcData_u08_Oper: operation=GetSigImcData_u08.Oper, timeout=0
          sync call SC_SetNtcSts_Oper: operation=SetNtcSts.Oper, timeout=0
        Customer_DID_ConditionCheckRead
        DataServices_DID_205A_Torque_Steer_Compensation_Activation_Counter_ReadData
        DataServices_DID_205A_Torque_Steer_Compensation_Activation_Counter_WriteData
        DataServices_DID_205B_Brake_Pull_Reduction_Activation_Counter_ReadData
        DataServices_DID_205B_Brake_Pull_Reduction_Activation_Counter_WriteData
        DataServices_DID_3003_Gear_Hardware_Part_Number_ReadData
        DataServices_DID_3003_Gear_Hardware_Part_Number_WriteData
        DataServices_DID_301A_Pull_Drift_Compensation_Value_ReadData
        DataServices_DID_301A_Pull_Drift_Compensation_Value_WriteData
        DataServices_DID_301F_Steering_Pinion_Rotation_Speed_ReadData
        DataServices_DID_3020_Steering_Pinion_Angle_ReadData
        DataServices_DID_330C_Steering_Shaft_Torque_Sensor_2_ReadData
        DataServices_DID_3B4B_Steering_wheel_angle_alignment_offset_ReadData
        DataServices_DID_630F_Multiple_VIN_Storage_Original_VIN_ReadData
        DataServices_DID_D100_Active_Diagnostic_Session_ReadData
        DataServices_DID_D111_ECU_Power_Supply_Voltage_ReadData
        DataServices_DID_D117_ECU_Internal_Temperature_ReadData
          data-receive-point-by-arguments:
            access REC_EcuTFild_Val: accessed-variable=EcuTFild.Val
        DataServices_DID_D118_Motor_Current_ReadData
        DataServices_DID_DD00_Global_Real_Time_ReadData
          data-receive-point-by-arguments:
            access REC_FordVehGlbRealTi_Val: accessed-variable=FordVehGlbRealTi.Val
        DataServices_DID_DD01_Total_Distance_ReadData
        DataServices_DID_DD09_Vehicle_Speed_ReadData
        DataServices_DID_DE00_VehicleData_ReadData
        DataServices_DID_DE00_VehicleData_WriteData
        DataServices_DID_DE01_FIHSwFeatureConfig_ReadData
        DataServices_DID_DE01_FIHSwFeatureConfig_WriteData
        DataServices_DID_DE02_FeatureConfig_ReadData
        DataServices_DID_DE02_FeatureConfig_WriteData
        DataServices_DID_DE03_Enable_DisableDTCs_ReadData
        DataServices_DID_DE03_Enable_DisableDTCs_WriteData
        DataServices_DID_DE04_PDCResetValue_ReadData
        DataServices_DID_DE04_PDCResetValue_WriteData
        DataServices_DID_DE05_Unused_ReadData
        DataServices_DID_DE05_Unused_WriteData
        DataServices_DID_EE00_DevMessConfig_ReadData
        DataServices_DID_EE00_DevMessConfig_WriteData
        DataServices_DID_EE01_XCP_Enable_Disable_ReadData
        DataServices_DID_EE01_XCP_Enable_Disable_WriteData
        DataServices_DID_EE02_Assist_On_Off_ReadData
        DataServices_DID_EE02_Assist_On_Off_WriteData
        DataServices_DID_EE03_IgnCycleCounter_ReadData
        DataServices_DID_EE04_IgnOnTime_ReadData
        DataServices_DID_EE05_FinalMotTq_ReadData
        DataServices_DID_EE06_VINChanged_ReadData
        DataServices_DID_EE07_EPSSystemState_ReadData
          data-receive-point-by-arguments:
            access REC_FordEpsSysSt_Val: accessed-variable=FordEpsSysSt.Val
        DataServices_DID_EE20_LoAFaultReporting_ReadData
        DataServices_DID_EE21_CurrentLvlCounter_ReadData
        DataServices_DID_EE22_VoltageLvlCounters_ReadData
        DataServices_DID_EE23_TempLvlCounters_ReadData
        DataServices_DID_EE40_ResearchMessConfig_ReadData
        DataServices_DID_EE40_ResearchMessConfig_WriteData
        DataServices_DID_EE41_ResearchFeatureSwitch_ReadData
        DataServices_DID_EE41_ResearchFeatureSwitch_WriteData
        DataServices_DID_EE42_ActiveFeatures_ReadData
        DataServices_DID_EE43_SDMSteeringMode_ReadData
        DataServices_DID_EE80_FIHSwVer_ReadData
        DataServices_DID_EE81_FIHSwReserved0_ReadData
        DataServices_DID_EE81_FIHSwReserved0_WriteData
        DataServices_DID_EE82_FIHSwReserved1_ReadData
        DataServices_DID_EE82_FIHSwReserved1_WriteData
        DataServices_DID_EE83_FIHSwReserved2_ReadData
        DataServices_DID_EE83_FIHSwReserved2_WriteData
        DataServices_DID_EE84_FIHSwReserved3_ReadData
        DataServices_DID_EE84_FIHSwReserved3_WriteData
        DataServices_DID_EE85_FIHSwReserved4_ReadData
        DataServices_DID_EE85_FIHSwReserved4_WriteData
        DataServices_DID_EE86_FIHSwReserved5_ReadData
        DataServices_DID_EE86_FIHSwReserved5_WriteData
        DataServices_DID_EE87_FIHSwReserved6_ReadData
        DataServices_DID_EE87_FIHSwReserved6_WriteData
        DataServices_DID_EE88_FIHSwReserved7_ReadData
        DataServices_DID_EE88_FIHSwReserved7_WriteData
        DataServices_DID_EED0_SupplierFactoryMode_ReadData
        DataServices_DID_EED0_SupplierFactoryMode_WriteData
        DataServices_DID_EED1_SupplierInternalFaultCode_ReadData
        DataServices_DID_EED2_SupplierInternalErrorMemory_ReadData
        DataServices_DID_F10A_ECU_Cal_Config_Part_Number_ReadData
        DataServices_DID_F110_Subsystem_Specific_Diagnostic_Specification_Part_Number_ReadData
        DataServices_DID_F110_Subsystem_Specific_Diagnostic_Specification_Part_Number_WriteData
        DataServices_DID_F111_ECU_Core_Assembly_Number_ReadData
        DataServices_DID_F111_ECU_Core_Assembly_Number_WriteData
        DataServices_DID_F113_ECU_Delivery_Assembly_Number_ReadData
        DataServices_DID_F113_ECU_Delivery_Assembly_Number_WriteData
        DataServices_DID_F124_ECU_Calibration_Data_1_Number_ReadData
        DataServices_DID_F15F_NOS_Generation_Tool_Version_Number_ReadData
        DataServices_DID_F162_Software_Download_Specification_Version_ReadData
        DataServices_DID_F162_Software_Download_Specification_Version_WriteData
        DataServices_DID_F163_Diagnostic_Specification_Version_ReadData
        DataServices_DID_F163_Diagnostic_Specification_Version_WriteData
        DataServices_DID_F166_NOS_Message_Database_1_Version_Number_ReadData
        DataServices_DID_F166_NOS_Message_Database_1_Version_Number_WriteData
        DataServices_DID_F17C_NOS_Bootloader_Generation_Tool_Version_Number_ReadData
        DataServices_DID_F180_Boot_Software_Identification_ReadData
        DataServices_DID_F188_Vehicle_Manufacturer_ECU_Software_Number_ReadData
        DataServices_DID_F18A_System_Supplier_Identifier_ReadData
        DataServices_DID_F18A_System_Supplier_Identifier_WriteData
        DataServices_DID_F18C_ECU_Serial_Number_ReadData
        DataServices_DID_F18C_ECU_Serial_Number_WriteData
        DataServices_DID_F190_Vehicle_Identification_Number_ReadData
        RoutineServices_RTN_0202_On_Demand_Self_Test_RequestResults
        RoutineServices_RTN_0202_On_Demand_Self_Test_Start
        RoutineServices_RTN_0202_On_Demand_Self_Test_Stop
        RoutineServices_RTN_200E_Calibrate_Steering_Angle_Centre_Position_Start
        RoutineServices_RTN_200F_Clear_Steering_Angle_Centre_Position_Calibration_Start
        RoutineServices_RTN_DC00_Reset_Assist_Fault_Counters_Start
        ServiceRequestNotification_Confirmation
        ServiceRequestNotification_Indication
      39 x swc service dependency:
        NvMDid205A: assigned-datas=[{role=ramBlock, used-data-element=Did205A}, {role=defaultValue, used-parameter-element=Did205ADft}], assigned-ports=role-based-port-assignment={port-prototype=Did205A, role=NvMService_AC3_SRBS_Defs}
          service-needs:
            nv block needs NvMDid205A: n-data-sets=0, readonly=false, reliability=ERROR-DETECTION, resistant-to-changed-sw=true, restore-at-start=true, store-at-shutdown=true, write-only-once=false, writing-frequency=0, writing-priority=LOW
        NvMDid205B: assigned-datas=[{role=ramBlock, used-data-element=Did205B}, {role=defaultValue, used-parameter-element=Did205BDft}], assigned-ports=role-based-port-assignment={port-prototype=Did205B, role=NvMService_AC3_SRBS_Defs}
          service-needs:
            nv block needs NvMDid205B: n-data-sets=0, readonly=false, reliability=ERROR-DETECTION, resistant-to-changed-sw=true, restore-at-start=true, store-at-shutdown=true, write-only-once=false, writing-frequency=0, writing-priority=LOW
        NvMDid3003: assigned-datas=[{role=ramBlock, used-data-element=Did3003}, {role=defaultValue, used-parameter-element=Did3003Dft}], assigned-ports=role-based-port-assignment={port-prototype=Did3003, role=NvMService_AC3_SRBS_Defs}
          service-needs:
            nv block needs NvMDid3003: n-data-sets=0, readonly=false, reliability=ERROR-DETECTION, resistant-to-changed-sw=true, restore-at-start=true, store-at-shutdown=true, write-only-once=false, writing-frequency=0, writing-priority=LOW
        NvMDid301A: assigned-datas=[{role=ramBlock, used-data-element=Did301A}, {role=defaultValue, used-parameter-element=Did301ADft}], assigned-ports=role-based-port-assignment={port-prototype=Did301A, role=NvMService_AC3_SRBS_Defs}
          service-needs:
            nv block needs NvMDid301A: n-data-sets=0, readonly=false, reliability=ERROR-DETECTION, resistant-to-changed-sw=true, restore-at-start=true, store-at-shutdown=true, write-only-once=false, writing-frequency=0, writing-priority=LOW
        NvMDid630F: assigned-datas=[{role=ramBlock, used-data-element=Did630F}, {role=defaultValue, used-parameter-element=Did630FDft}], assigned-ports=role-based-port-assignment={port-prototype=Did630F, role=NvMService_AC3_SRBS_Defs}
          service-needs:
            nv block needs NvMDid630F: n-data-sets=0, readonly=false, reliability=ERROR-DETECTION, resistant-to-changed-sw=true, restore-at-start=true, store-at-shutdown=true, write-only-once=false, writing-frequency=0, writing-priority=LOW
        NvMDid630FChk: assigned-ports=role-based-port-assignment={port-prototype=Did630FChk, role=NvMService_AC3_SRBS_Defs}
          assigned-datas:
            role=ramBlock, used-data-element=Did630FChk
            role=defaultValue, used-parameter-element=Did630FChkDft
          service-needs:
            nv block needs NvMDid630FChk: n-data-sets=0, readonly=false, reliability=ERROR-DETECTION, resistant-to-changed-sw=true, restore-at-start=true, store-at-shutdown=true, write-only-once=false, writing-frequency=0, writing-priority=LOW
        NvMDidDE00: assigned-datas=[{role=ramBlock, used-data-element=DidDE00}, {role=defaultValue, used-parameter-element=DidDE00Dft}], assigned-ports=role-based-port-assignment={port-prototype=DidDE00, role=NvMService_AC3_SRBS_Defs}
          service-needs:
            nv block needs NvMDidDE00: n-data-sets=0, readonly=false, reliability=ERROR-DETECTION, resistant-to-changed-sw=true, restore-at-start=true, store-at-shutdown=true, write-only-once=false, writing-frequency=0, writing-priority=LOW
        NvMDidDE01: assigned-datas=[{role=ramBlock, used-data-element=DidDE01}, {role=defaultValue, used-parameter-element=DidDE01Dft}], assigned-ports=role-based-port-assignment={port-prototype=DidDE01, role=NvMService_AC3_SRBS_Defs}
          service-needs:
            nv block needs NvMDidDE01: n-data-sets=0, readonly=false, reliability=ERROR-DETECTION, resistant-to-changed-sw=true, restore-at-start=true, store-at-shutdown=true, write-only-once=false, writing-frequency=0, writing-priority=LOW
        NvMDidDE02: assigned-datas=[{role=ramBlock, used-data-element=DidDE02}, {role=defaultValue, used-parameter-element=DidDE02Dft}], assigned-ports=role-based-port-assignment={port-prototype=DidDE02, role=NvMService_AC3_SRBS_Defs}
          service-needs:
            nv block needs NvMDidDE02: n-data-sets=0, readonly=false, reliability=ERROR-DETECTION, resistant-to-changed-sw=true, restore-at-start=true, store-at-shutdown=true, write-only-once=false, writing-frequency=0, writing-priority=LOW
        NvMDidDE03: assigned-datas=[{role=ramBlock, used-data-element=DidDE03}, {role=defaultValue, used-parameter-element=DidDE03Dft}], assigned-ports=role-based-port-assignment={port-prototype=DidDE03, role=NvMService_AC3_SRBS_Defs}
          service-needs:
            nv block needs NvMDidDE03: n-data-sets=0, readonly=false, reliability=ERROR-DETECTION, resistant-to-changed-sw=true, restore-at-start=true, store-at-shutdown=true, write-only-once=false, writing-frequency=0, writing-priority=LOW
        NvMDidDE04: assigned-datas=[{role=ramBlock, used-data-element=DidDE04}, {role=defaultValue, used-parameter-element=DidDE04Dft}], assigned-ports=role-based-port-assignment={port-prototype=DidDE04, role=NvMService_AC3_SRBS_Defs}
          service-needs:
            nv block needs NvMDidDE04: n-data-sets=0, readonly=false, reliability=ERROR-DETECTION, resistant-to-changed-sw=true, restore-at-start=true, store-at-shutdown=true, write-only-once=false, writing-frequency=0, writing-priority=LOW
        NvMDidDE05: assigned-datas=[{role=ramBlock, used-data-element=DidDE05}, {role=defaultValue, used-parameter-element=DidDE05Dft}], assigned-ports=role-based-port-assignment={port-prototype=DidDE05, role=NvMService_AC3_SRBS_Defs}
          service-needs:
            nv block needs NvMDidDE05: n-data-sets=0, readonly=false, reliability=ERROR-DETECTION, resistant-to-changed-sw=true, restore-at-start=true, store-at-shutdown=true, write-only-once=false, writing-frequency=0, writing-priority=LOW
        NvMDidEE00: assigned-datas=[{role=ramBlock, used-data-element=DidEE00}, {role=defaultValue, used-parameter-element=DidEE00Dft}], assigned-ports=role-based-port-assignment={port-prototype=DidEE00, role=NvMService_AC3_SRBS_Defs}
          service-needs:
            nv block needs NvMDidEE00: n-data-sets=0, readonly=false, reliability=ERROR-DETECTION, resistant-to-changed-sw=true, restore-at-start=true, store-at-shutdown=true, write-only-once=false, writing-frequency=0, writing-priority=LOW
        NvMDidEE01: assigned-datas=[{role=ramBlock, used-data-element=DidEE01}, {role=defaultValue, used-parameter-element=DidEE01Dft}], assigned-ports=role-based-port-assignment={port-prototype=DidEE01, role=NvMService_AC3_SRBS_Defs}
          service-needs:
            nv block needs NvMDidEE01: n-data-sets=0, readonly=false, reliability=ERROR-DETECTION, resistant-to-changed-sw=true, restore-at-start=true, store-at-shutdown=true, write-only-once=false, writing-frequency=0, writing-priority=LOW
        NvMDidEE02: assigned-datas=[{role=ramBlock, used-data-element=DidEE02}, {role=defaultValue, used-parameter-element=DidEE02Dft}], assigned-ports=role-based-port-assignment={port-prototype=DidEE02, role=NvMService_AC3_SRBS_Defs}
          service-needs:
            nv block needs NvMDidEE02: n-data-sets=0, readonly=false, reliability=ERROR-DETECTION, resistant-to-changed-sw=true, restore-at-start=true, store-at-shutdown=true, write-only-once=false, writing-frequency=0, writing-priority=LOW
        NvMDidEE21: assigned-datas=[{role=ramBlock, used-data-element=DidEE21}, {role=defaultValue, used-parameter-element=DidEE21Dft}], assigned-ports=role-based-port-assignment={port-prototype=DidEE21, role=NvMService_AC3_SRBS_Defs}
          service-needs:
            nv block needs NvMDidEE21: n-data-sets=0, readonly=false, reliability=ERROR-DETECTION, resistant-to-changed-sw=true, restore-at-start=true, store-at-shutdown=true, write-only-once=false, writing-frequency=0, writing-priority=LOW
        NvMDidEE22: assigned-datas=[{role=ramBlock, used-data-element=DidEE22}, {role=defaultValue, used-parameter-element=DidEE22Dft}], assigned-ports=role-based-port-assignment={port-prototype=DidEE22, role=NvMService_AC3_SRBS_Defs}
          service-needs:
            nv block needs NvMDidEE22: n-data-sets=0, readonly=false, reliability=ERROR-DETECTION, resistant-to-changed-sw=true, restore-at-start=true, store-at-shutdown=true, write-only-once=false, writing-frequency=0, writing-priority=LOW
        NvMDidEE23: assigned-datas=[{role=ramBlock, used-data-element=DidEE23}, {role=defaultValue, used-parameter-element=DidEE23Dft}], assigned-ports=role-based-port-assignment={port-prototype=DidEE23, role=NvMService_AC3_SRBS_Defs}
          service-needs:
            nv block needs NvMDidEE23: n-data-sets=0, readonly=false, reliability=ERROR-DETECTION, resistant-to-changed-sw=true, restore-at-start=true, store-at-shutdown=true, write-only-once=false, writing-frequency=0, writing-priority=LOW
        NvMDidEE40: assigned-datas=[{role=ramBlock, used-data-element=DidEE40}, {role=defaultValue, used-parameter-element=DidEE40Dft}], assigned-ports=role-based-port-assignment={port-prototype=DidEE40, role=NvMService_AC3_SRBS_Defs}
          service-needs:
            nv block needs NvMDidEE40: n-data-sets=0, readonly=false, reliability=ERROR-DETECTION, resistant-to-changed-sw=true, restore-at-start=true, store-at-shutdown=true, write-only-once=false, writing-frequency=0, writing-priority=LOW
        NvMDidEE41: assigned-datas=[{role=ramBlock, used-data-element=DidEE41}, {role=defaultValue, used-parameter-element=DidEE41Dft}], assigned-ports=role-based-port-assignment={port-prototype=DidEE41, role=NvMService_AC3_SRBS_Defs}
          service-needs:
            nv block needs NvMDidEE41: n-data-sets=0, readonly=false, reliability=ERROR-DETECTION, resistant-to-changed-sw=true, restore-at-start=true, store-at-shutdown=true, write-only-once=false, writing-frequency=0, writing-priority=LOW
        NvMDidEE81: assigned-datas=[{role=ramBlock, used-data-element=DidEE81}, {role=defaultValue, used-parameter-element=DidEE81Dft}], assigned-ports=role-based-port-assignment={port-prototype=DidEE81, role=NvMService_AC3_SRBS_Defs}
          service-needs:
            nv block needs NvMDidEE81: n-data-sets=0, readonly=false, reliability=ERROR-DETECTION, resistant-to-changed-sw=true, restore-at-start=true, store-at-shutdown=true, write-only-once=false, writing-frequency=0, writing-priority=LOW
        NvMDidEE82: assigned-datas=[{role=ramBlock, used-data-element=DidEE82}, {role=defaultValue, used-parameter-element=DidEE82Dft}], assigned-ports=role-based-port-assignment={port-prototype=DidEE82, role=NvMService_AC3_SRBS_Defs}
          service-needs:
            nv block needs NvMDidEE82: n-data-sets=0, readonly=false, reliability=ERROR-DETECTION, resistant-to-changed-sw=true, restore-at-start=true, store-at-shutdown=true, write-only-once=false, writing-frequency=0, writing-priority=LOW
        NvMDidEE83: assigned-datas=[{role=ramBlock, used-data-element=DidEE83}, {role=defaultValue, used-parameter-element=DidEE83Dft}], assigned-ports=role-based-port-assignment={port-prototype=DidEE83, role=NvMService_AC3_SRBS_Defs}
          service-needs:
            nv block needs NvMDidEE83: n-data-sets=0, readonly=false, reliability=ERROR-DETECTION, resistant-to-changed-sw=true, restore-at-start=true, store-at-shutdown=true, write-only-once=false, writing-frequency=0, writing-priority=LOW
        NvMDidEE84: assigned-datas=[{role=ramBlock, used-data-element=DidEE84}, {role=defaultValue, used-parameter-element=DidEE84Dft}], assigned-ports=role-based-port-assignment={port-prototype=DidEE84, role=NvMService_AC3_SRBS_Defs}
          service-needs:
            nv block needs NvMDidEE84: n-data-sets=0, readonly=false, reliability=ERROR-DETECTION, resistant-to-changed-sw=true, restore-at-start=true, store-at-shutdown=true, write-only-once=false, writing-frequency=0, writing-priority=LOW
        NvMDidEE85: assigned-datas=[{role=ramBlock, used-data-element=DidEE85}, {role=defaultValue, used-parameter-element=DidEE85Dft}], assigned-ports=role-based-port-assignment={port-prototype=DidEE85, role=NvMService_AC3_SRBS_Defs}
          service-needs:
            nv block needs NvMDidEE85: n-data-sets=0, readonly=false, reliability=ERROR-DETECTION, resistant-to-changed-sw=true, restore-at-start=true, store-at-shutdown=true, write-only-once=false, writing-frequency=0, writing-priority=LOW
        NvMDidEE86: assigned-datas=[{role=ramBlock, used-data-element=DidEE86}, {role=defaultValue, used-parameter-element=DidEE86Dft}], assigned-ports=role-based-port-assignment={port-prototype=DidEE86, role=NvMService_AC3_SRBS_Defs}
          service-needs:
            nv block needs NvMDidEE86: n-data-sets=0, readonly=false, reliability=ERROR-DETECTION, resistant-to-changed-sw=true, restore-at-start=true, store-at-shutdown=true, write-only-once=false, writing-frequency=0, writing-priority=LOW
        NvMDidEE87: assigned-datas=[{role=ramBlock, used-data-element=DidEE87}, {role=defaultValue, used-parameter-element=DidEE87Dft}], assigned-ports=role-based-port-assignment={port-prototype=DidEE87, role=NvMService_AC3_SRBS_Defs}
          service-needs:
            nv block needs NvMDidEE87: n-data-sets=0, readonly=false, reliability=ERROR-DETECTION, resistant-to-changed-sw=true, restore-at-start=true, store-at-shutdown=true, write-only-once=false, writing-frequency=0, writing-priority=LOW
        NvMDidEE88: assigned-datas=[{role=ramBlock, used-data-element=DidEE88}, {role=defaultValue, used-parameter-element=DidEE88Dft}], assigned-ports=role-based-port-assignment={port-prototype=DidEE88, role=NvMService_AC3_SRBS_Defs}
          service-needs:
            nv block needs NvMDidEE88: n-data-sets=0, readonly=false, reliability=ERROR-DETECTION, resistant-to-changed-sw=true, restore-at-start=true, store-at-shutdown=true, write-only-once=false, writing-frequency=0, writing-priority=LOW
        NvMDidEED0: assigned-datas=[{role=ramBlock, used-data-element=DidEED0}, {role=defaultValue, used-parameter-element=DidEED0Dft}], assigned-ports=role-based-port-assignment={port-prototype=DidEED0, role=NvMService_AC3_SRBS_Defs}
          service-needs:
            nv block needs NvMDidEED0: n-data-sets=0, readonly=false, reliability=ERROR-DETECTION, resistant-to-changed-sw=true, restore-at-start=true, store-at-shutdown=true, write-only-once=false, writing-frequency=0, writing-priority=LOW
        NvMDidF110: assigned-datas=[{role=ramBlock, used-data-element=DidF110}, {role=defaultValue, used-parameter-element=DidF110Dft}], assigned-ports=role-based-port-assignment={port-prototype=DidF110, role=NvMService_AC3_SRBS_Defs}
          service-needs:
            nv block needs NvMDidF110: n-data-sets=0, readonly=false, reliability=ERROR-DETECTION, resistant-to-changed-sw=true, restore-at-start=true, store-at-shutdown=true, write-only-once=false, writing-frequency=0, writing-priority=LOW
        NvMDidF111: assigned-datas=[{role=ramBlock, used-data-element=DidF111}, {role=defaultValue, used-parameter-element=DidF111Dft}], assigned-ports=role-based-port-assignment={port-prototype=DidF111, role=NvMService_AC3_SRBS_Defs}
          service-needs:
            nv block needs NvMDidF111: n-data-sets=0, readonly=false, reliability=ERROR-DETECTION, resistant-to-changed-sw=true, restore-at-start=true, store-at-shutdown=true, write-only-once=false, writing-frequency=0, writing-priority=LOW
        NvMDidF113: assigned-datas=[{role=ramBlock, used-data-element=DidF113}, {role=defaultValue, used-parameter-element=DidF113Dft}], assigned-ports=role-based-port-assignment={port-prototype=DidF113, role=NvMService_AC3_SRBS_Defs}
          service-needs:
            nv block needs NvMDidF113: n-data-sets=0, readonly=false, reliability=ERROR-DETECTION, resistant-to-changed-sw=true, restore-at-start=true, store-at-shutdown=true, write-only-once=false, writing-frequency=0, writing-priority=LOW
        NvMDidF15F: assigned-datas=[{role=ramBlock, used-data-element=DidF15F}, {role=defaultValue, used-parameter-element=DidF15FDft}], assigned-ports=role-based-port-assignment={port-prototype=DidF15F, role=NvMService_AC3_SRBS_Defs}
          service-needs:
            nv block needs NvMDidF15F: n-data-sets=0, readonly=false, reliability=ERROR-DETECTION, resistant-to-changed-sw=true, restore-at-start=true, store-at-shutdown=true, write-only-once=false, writing-frequency=0, writing-priority=LOW
        NvMDidF162: assigned-datas=[{role=ramBlock, used-data-element=DidF162}, {role=defaultValue, used-parameter-element=DidF162Dft}], assigned-ports=role-based-port-assignment={port-prototype=DidF162, role=NvMService_AC3_SRBS_Defs}
          service-needs:
            nv block needs NvMDidF162: n-data-sets=0, readonly=false, reliability=ERROR-DETECTION, resistant-to-changed-sw=true, restore-at-start=true, store-at-shutdown=true, write-only-once=false, writing-frequency=0, writing-priority=LOW
        NvMDidF163: assigned-datas=[{role=ramBlock, used-data-element=DidF163}, {role=defaultValue, used-parameter-element=DidF163Dft}], assigned-ports=role-based-port-assignment={port-prototype=DidF163, role=NvMService_AC3_SRBS_Defs}
          service-needs:
            nv block needs NvMDidF163: n-data-sets=0, readonly=false, reliability=ERROR-DETECTION, resistant-to-changed-sw=true, restore-at-start=true, store-at-shutdown=true, write-only-once=false, writing-frequency=0, writing-priority=LOW
        NvMDidF166: assigned-datas=[{role=ramBlock, used-data-element=DidF166}, {role=defaultValue, used-parameter-element=DidF166Dft}], assigned-ports=role-based-port-assignment={port-prototype=DidF166, role=NvMService_AC3_SRBS_Defs}
          service-needs:
            nv block needs NvMDidF166: n-data-sets=0, readonly=false, reliability=ERROR-DETECTION, resistant-to-changed-sw=true, restore-at-start=true, store-at-shutdown=true, write-only-once=false, writing-frequency=0, writing-priority=LOW
        NvMDidF18A: assigned-datas=[{role=ramBlock, used-data-element=DidF18A}, {role=defaultValue, used-parameter-element=DidF18ADft}], assigned-ports=role-based-port-assignment={port-prototype=DidF18A, role=NvMService_AC3_SRBS_Defs}
          service-needs:
            nv block needs NvMDidF18A: n-data-sets=0, readonly=false, reliability=ERROR-DETECTION, resistant-to-changed-sw=true, restore-at-start=true, store-at-shutdown=true, write-only-once=false, writing-frequency=0, writing-priority=LOW
        NvMDidF18C: assigned-datas=[{role=ramBlock, used-data-element=DidF18C}, {role=defaultValue, used-parameter-element=DidF18CDft}], assigned-ports=role-based-port-assignment={port-prototype=DidF18C, role=NvMService_AC3_SRBS_Defs}
          service-needs:
            nv block needs NvMDidF18C: n-data-sets=0, readonly=false, reliability=ERROR-DETECTION, resistant-to-changed-sw=true, restore-at-start=true, store-at-shutdown=true, write-only-once=false, writing-frequency=0, writing-priority=LOW
        NvMDidF190: assigned-datas=[{role=ramBlock, used-data-element=DidF190}, {role=defaultValue, used-parameter-element=DidF190Dft}], assigned-ports=role-based-port-assignment={port-prototype=DidF190, role=NvMService_AC3_SRBS_Defs}
          service-needs:
            nv block needs NvMDidF190: n-data-sets=0, readonly=false, reliability=ERROR-DETECTION, resistant-to-changed-sw=true, restore-at-start=true, store-at-shutdown=true, write-only-once=false, writing-frequency=0, writing-priority=LOW
      shared-parameters:
        39 x parameter data prototype, all with sw-calibration-access=READ-WRITE:
          Did205ADft: type=Ary1D_u8_2, init-value=[0, 0]
          Did205BDft: type=Ary1D_u8_2, init-value=[0, 0]
          Did3003Dft: type=Ary1D_u8_24, init-value=24 x 0
          Did301ADft: type=Ary1D_u8_2, init-value=[0, 0]
          Did630FChkDft: type=boolean, init-value=0
          Did630FDft: type=Ary1D_u8_24, init-value=24 x 0
          DidDE00Dft: type=Ary1D_u8_24, init-value=[0, 0, 0, 0, 0, 0, 2, 0, 0, 0, 0, 0, 0, 0, 0, 0, 0, 0, 0, 0, 0, 0, 0, 0]
          DidDE01Dft: type=Ary1D_u8_24, init-value=24 x 0
          DidDE02Dft: type=Ary1D_u8_24, init-value=[0, 0, 0, 0, 0, 0, 2, 0, 0, 0, 0, 0, 0, 0, 0, 0, 0, 0, 0, 0, 0, 0, 0, 0]
          DidDE03Dft: type=Ary1D_u8_64, init-value=[0, 255, 255, 255, 255, 255, 255, 255, 255, 255, 255, 255, 255, 255, 255, 255, 255, 255, 255, 255, 255, 255, 255, 255, 255, 255, 255, 255, 255, 255, 255, 255, 255, 255, 255, 255, 255, 255, 255, 255, 255, 255, 255, 255, 255, 255, 255, 255, 255, 255, 255, 255, 255, 255, 255, 255, 255, 255, 255, 255, 255, 255, 255, 255]
          DidDE04Dft: type=Ary1D_u8_2, init-value=[255, 255]
          DidDE05Dft: type=Ary1D_u8_24, init-value=24 x 0
          DidEE00Dft: type=Ary1D_u8_3, init-value=[0, 0, 0]
          DidEE01Dft: type=uint8, init-value=0
          DidEE02Dft: type=uint8, init-value=255
          DidEE21Dft: type=Ary1D_u8_20, init-value=20 x 0
          DidEE22Dft: type=Ary1D_u8_40, init-value=40 x 0
          DidEE23Dft: type=Ary1D_u8_40, init-value=[0, 0, 0, 0, 0, 0, 0, 0, 0, 0, 0, 0, 0, 0, 0, 0, 0, 0, 0, 0, 255, 255, 255, 255, 255, 255, 255, 255, 255, 255, 255, 255, 255, 255, 255, 255, 255, 255, 255, 255]
          DidEE40Dft: type=Ary1D_u8_3, init-value=[0, 0, 0]
          DidEE41Dft: type=uint8, init-value=0
          DidEE{81..88}Dft: type=Ary1D_u8_4, init-value=[0, 0, 0, 0]
          DidEED0Dft: type=uint8, init-value=0
          DidF110Dft: type=Ary1D_u8_24, init-value=24 x 0
          DidF111Dft: type=Ary1D_u8_24, init-value=24 x 0
          DidF113Dft: type=Ary1D_u8_24, init-value=24 x 0
          DidF15FDft: type=Ary1D_u8_10, init-value=10 x 0
          DidF162Dft: type=uint8, init-value=0
          DidF163Dft: type=uint8, init-value=0
          DidF166Dft: type=Ary1D_u8_4, init-value=[0, 0, 0, 0]
          DidF18ADft: type=Ary1D_u8_24, init-value=24 x 0
          DidF18CDft: type=Ary1D_u8_16, init-value=16 x 0
          DidF190Dft: type=Ary1D_u8_24, init-value=24 x 0
  swc implementation CustDiag_Implementation: behavior=CustDiag_InternalBehavior
    code-descriptors:
      code Default: artifact-descriptors=autosar-engineering-object={short-label=Default, category=SWSRC}
